VERSION ""

NS_ :

BS_:

BU_: VCU BMS DD STMM MM5 PDM MM52 RAND

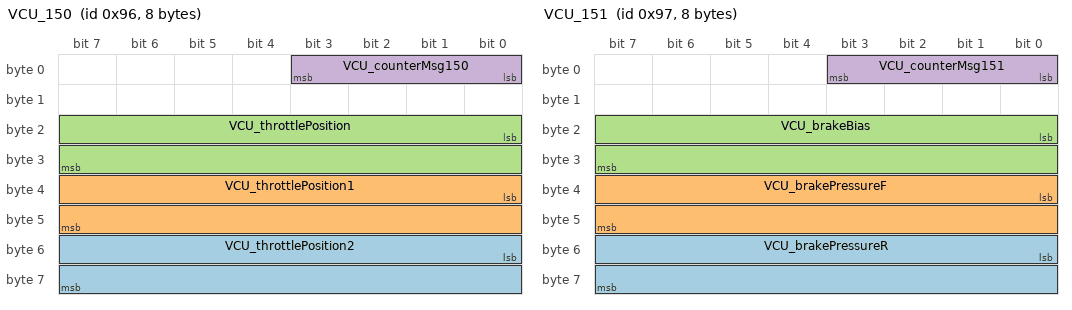
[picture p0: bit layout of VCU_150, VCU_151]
BO_ 150 VCU_150: 8 VCU
 SG_ VCU_throttlePosition2 : 48|16@1- (0.1,0) [0|100] "%" Vector__XXX
 SG_ VCU_throttlePosition1 : 32|16@1- (0.1,0) [0|100] "%" Vector__XXX
 SG_ VCU_throttlePosition : 16|16@1- (0.1,0) [0|100] "%" Vector__XXX
 SG_ VCU_counterMsg150 : 0|4@1+ (1,0) [0|15] "" Vector__XXX

BO_ 151 VCU_151: 8 VCU
 SG_ VCU_brakePressureR : 48|16@1- (0.1,0) [0|2000] "psi" Vector__XXX
 SG_ VCU_brakePressureF : 32|16@1- (0.1,0) [0|2000] "psi" Vector__XXX
 SG_ VCU_brakeBias : 16|16@1- (0.1,0) [-3276.8|3276.7] "%" Vector__XXX
 SG_ VCU_counterMsg151 : 0|4@1+ (1,0) [0|15] "" Vector__XXX

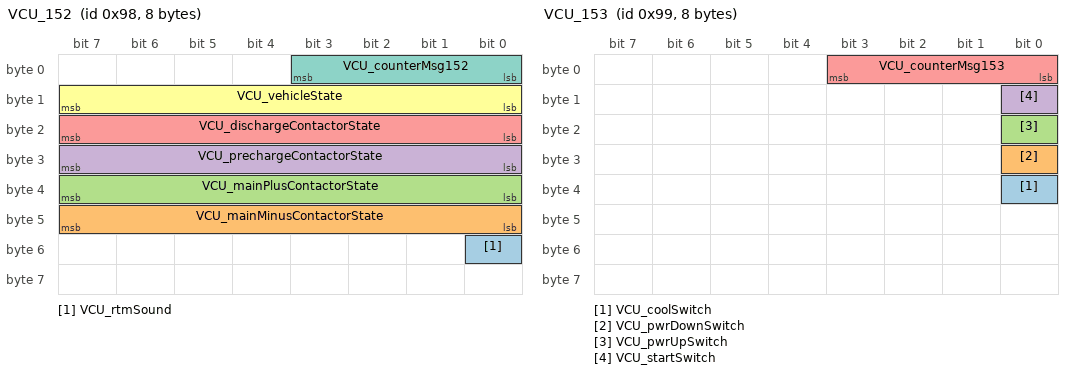
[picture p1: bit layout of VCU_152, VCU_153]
BO_ 152 VCU_152: 8 VCU
 SG_ VCU_rtmSound : 48|1@1+ (1,0) [0|1] "" Vector__XXX
 SG_ VCU_mainMinusContactorState : 40|8@1+ (1,0) [0|255] "" Vector__XXX
 SG_ VCU_mainPlusContactorState : 32|8@1+ (1,0) [0|255] "" Vector__XXX
 SG_ VCU_prechargeContactorState : 24|8@1+ (1,0) [0|255] "" Vector__XXX
 SG_ VCU_dischargeContactorState : 16|8@1+ (1,0) [0|255] "" Vector__XXX
 SG_ VCU_vehicleState : 8|8@1+ (1,0) [0|255] "" Vector__XXX
 SG_ VCU_counterMsg152 : 0|4@1+ (1,0) [0|15] "" Vector__XXX

BO_ 153 VCU_153: 8 VCU
 SG_ VCU_coolSwitch : 32|1@1+ (1,0) [0|1] "" Vector__XXX
 SG_ VCU_pwrDownSwitch : 24|1@1+ (1,0) [0|1] "" Vector__XXX
 SG_ VCU_pwrUpSwitch : 16|1@1+ (1,0) [0|1] "" Vector__XXX
 SG_ VCU_startSwitch : 8|1@1+ (1,0) [0|1] "" Vector__XXX
 SG_ VCU_counterMsg153 : 0|4@1+ (1,0) [0|15] "" Vector__XXX

BO_ 154 VCU_154: 8 VCU
 SG_ VCU_rotorTempFR : 32|16@1- (0.1,0) [-20|3276.7] "degC" Vector__XXX
 SG_ VCU_rotorTempFL : 16|16@1- (0.1,0) [-20|3276.7] "degC" Vector__XXX
 SG_ VCU_counterMsg154 : 0|4@1+ (1,0) [0|15] "" Vector__XXX

BO_ 155 VCU_155: 8 VCU
 SG_ VCU_rotorTempRR : 32|16@1- (0.1,0) [-20|3276.7] "degC" Vector__XXX
 SG_ VCU_rotorTempRL : 16|16@1- (0.1,0) [-20|3276.7] "degC" Vector__XXX
 SG_ VCU_counterMsg155 : 0|4@1+ (1,0) [0|15] "" Vector__XXX

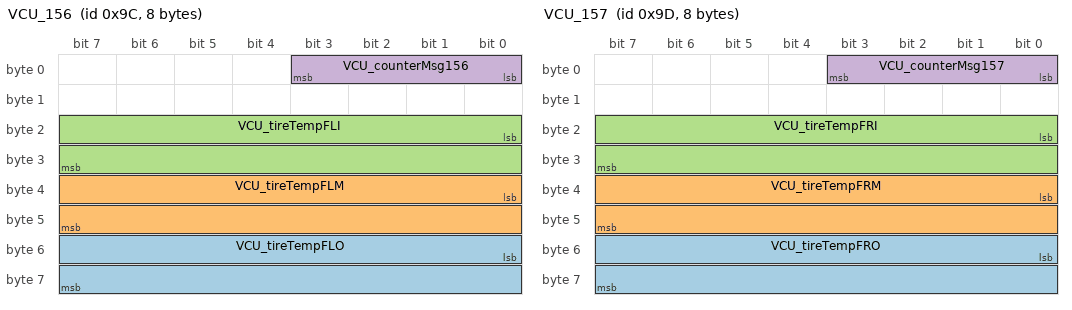
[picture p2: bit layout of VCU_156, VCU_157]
BO_ 156 VCU_156: 8 VCU
 SG_ VCU_tireTempFLO : 48|16@1- (0.1,0) [-20|3276.7] "degC" Vector__XXX
 SG_ VCU_tireTempFLM : 32|16@1- (0.1,0) [-20|3276.7] "degC" Vector__XXX
 SG_ VCU_tireTempFLI : 16|16@1- (0.1,0) [-20|3276.7] "degC" Vector__XXX
 SG_ VCU_counterMsg156 : 0|4@1+ (1,0) [0|15] "" Vector__XXX

BO_ 157 VCU_157: 8 VCU
 SG_ VCU_tireTempFRO : 48|16@1- (0.1,0) [-20|3276.7] "degC" Vector__XXX
 SG_ VCU_tireTempFRM : 32|16@1- (0.1,0) [-20|3276.7] "degC" Vector__XXX
 SG_ VCU_tireTempFRI : 16|16@1- (0.1,0) [-20|3276.7] "degC" Vector__XXX
 SG_ VCU_counterMsg157 : 0|4@1+ (1,0) [0|15] "" Vector__XXX

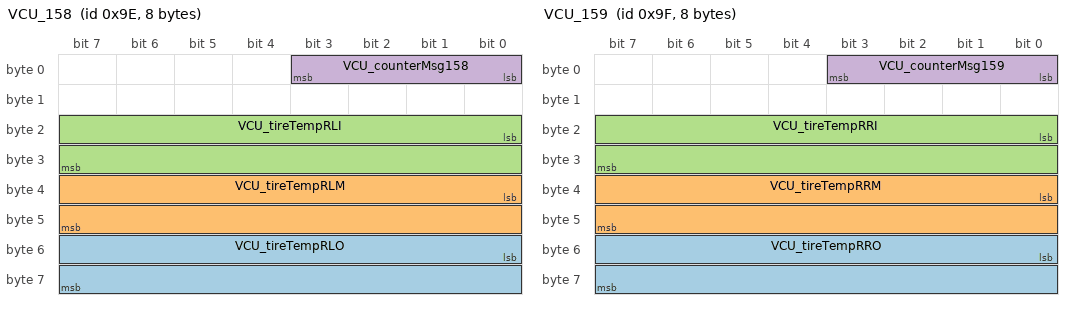
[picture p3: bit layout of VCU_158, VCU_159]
BO_ 158 VCU_158: 8 VCU
 SG_ VCU_tireTempRLO : 48|16@1- (0.1,0) [-20|3276.7] "degC" Vector__XXX
 SG_ VCU_tireTempRLM : 32|16@1- (0.1,0) [-20|3276.7] "degC" Vector__XXX
 SG_ VCU_tireTempRLI : 16|16@1- (0.1,0) [-20|3276.7] "degC" Vector__XXX
 SG_ VCU_counterMsg158 : 0|4@1+ (1,0) [0|15] "" Vector__XXX

BO_ 159 VCU_159: 8 VCU
 SG_ VCU_tireTempRRO : 48|16@1- (0.1,0) [-20|3276.7] "degC" Vector__XXX
 SG_ VCU_tireTempRRM : 32|16@1- (0.1,0) [-20|3276.7] "degC" Vector__XXX
 SG_ VCU_tireTempRRI : 16|16@1- (0.1,0) [-20|3276.7] "degC" Vector__XXX
 SG_ VCU_counterMsg159 : 0|4@1+ (1,0) [0|15] "" Vector__XXX

BO_ 160 VCU_160: 8 VCU
 SG_ VCU_driveSpeed : 16|16@1- (0.1,0) [-20|3276.7] "mph" Vector__XXX
 SG_ VCU_counterMsg160 : 0|4@1+ (1,0) [0|15] "" Vector__XXX

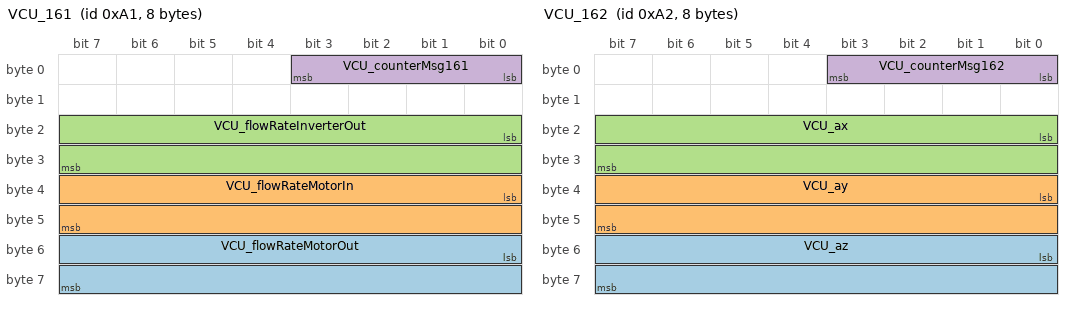
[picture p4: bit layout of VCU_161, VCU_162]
BO_ 161 VCU_161: 8 VCU
 SG_ VCU_flowRateMotorOut : 48|16@1- (0.1,0) [-10|30] "lpm" Vector__XXX
 SG_ VCU_flowRateMotorIn : 32|16@1- (0.1,0) [-10|30] "lpm" Vector__XXX
 SG_ VCU_flowRateInverterOut : 16|16@1- (0.1,0) [-10|30] "lpm" Vector__XXX
 SG_ VCU_counterMsg161 : 0|4@1+ (1,0) [0|15] "" Vector__XXX

BO_ 162 VCU_162: 8 VCU
 SG_ VCU_az : 48|16@1- (0.001,0) [-5|5] "g" Vector__XXX
 SG_ VCU_ay : 32|16@1- (0.001,0) [-5|5] "g" Vector__XXX
 SG_ VCU_ax : 16|16@1- (0.001,0) [-5|5] "g" Vector__XXX
 SG_ VCU_counterMsg162 : 0|4@1+ (1,0) [0|15] "" Vector__XXX

BO_ 163 VCU_163: 8 VCU
 SG_ VCU_susTravelRL : 48|16@1+ (0.001,0) [-100|100] "" Vector__XXX
 SG_ VCU_susTravelRR : 32|16@1+ (0.001,0) [-100|100] "" Vector__XXX
 SG_ VCU_susTravelFL : 16|16@1+ (0.001,0) [-100|100] "" Vector__XXX
 SG_ VCU_susTravelFR : 0|16@1+ (0.001,0) [-100|100] "" Vector__XXX

BO_ 164 VCU_164: 8 VCU
 SG_ VCU_torqueProfile : 16|16@1+ (1,0) [0|10] "en" Vector__XXX
 SG_ VCU_assistedTorque : 0|16@1- (0.1,0) [-230|230] "Nm" Vector__XXX

BO_ 200 BMS_200: 8 BMS
 SG_ BMS_packSOC : 48|8@1- (0.5,0) [0|100] "%" Vector__XXX
 SG_ BMS_packVolt : 32|16@1- (0.1,0) [-3276.8|3276.7] "V" Vector__XXX
 SG_ BMS_packCurr : 16|16@1- (0.1,0) [-3276.8|3276.7] "A" Vector__XXX
 SG_ BMS_rollingCounter200 : 0|8@1+ (1,0) [0|255] "" Vector__XXX

BO_ 201 BMS_201: 8 BMS
 SG_ BMS_minPackVolt : 48|16@1- (0.1,0) [-3276.8|3276.7] "V" Vector__XXX
 SG_ BMS_maxPackVolt : 32|16@1- (0.1,0) [-3276.8|3276.7] "V" Vector__XXX
 SG_ BMS_packSummedVolt : 16|16@1- (0.01,0) [-327.68|327.67] "V" Vector__XXX
 SG_ BMS_rollingCounter201 : 0|8@1+ (1,0) [0|255] "" Vector__XXX

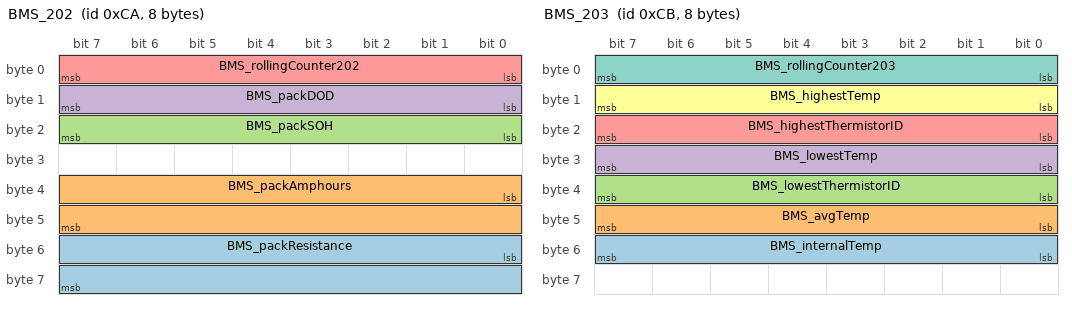
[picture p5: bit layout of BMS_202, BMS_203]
BO_ 202 BMS_202: 8 BMS
 SG_ BMS_packResistance : 48|16@1- (1,0) [-32768|32767] "mOhm" Vector__XXX
 SG_ BMS_packAmphours : 32|16@1- (0.1,0) [-3276.8|3276.7] "Ahr" Vector__XXX
 SG_ BMS_packSOH : 16|8@1- (1,0) [0|100] "%" Vector__XXX
 SG_ BMS_packDOD : 8|8@1- (0.5,0) [0|100] "%" Vector__XXX
 SG_ BMS_rollingCounter202 : 0|8@1+ (1,0) [0|255] "" Vector__XXX

BO_ 203 BMS_203: 8 BMS
 SG_ BMS_internalTemp : 48|8@1- (1,0) [-5|100] "degC" Vector__XXX
 SG_ BMS_avgTemp : 40|8@1- (1,0) [-5|100] "degC" Vector__XXX
 SG_ BMS_lowestThermistorID : 32|8@1+ (1,0) [1|180] "" Vector__XXX
 SG_ BMS_lowestTemp : 24|8@1- (1,0) [-5|100] "degC" Vector__XXX
 SG_ BMS_highestThermistorID : 16|8@1+ (1,0) [1|180] "" Vector__XXX
 SG_ BMS_highestTemp : 8|8@1- (1,0) [-5|100] "degC" Vector__XXX
 SG_ BMS_rollingCounter203 : 0|8@1+ (1,0) [0|255] "" Vector__XXX

BO_ 204 BMS_204: 8 BMS
 SG_ BMS_avgCellVolt : 48|16@1- (0.0001,0) [-3.2768|3.2767] "V" Vector__XXX
 SG_ BMS_highCellVolt : 32|16@1- (0.0001,0) [-3.2768|3.2767] "V" Vector__XXX
 SG_ BMS_lowCellVolt : 16|16@1- (0.0001,0) [-3.2768|3.2767] "V" Vector__XXX
 SG_ BMS_rollingCounter204 : 0|8@1+ (1,0) [0|255] "" Vector__XXX

BO_ 205 BMS_205: 8 BMS
 SG_ BMS_avgCellOpenVolt : 48|16@1- (0.0001,0) [-3.2768|3.2767] "V" Vector__XXX
 SG_ BMS_highCellOpenVolt : 32|16@1- (0.0001,0) [-3.2768|3.2767] "V" Vector__XXX
 SG_ BMS_lowCellOpenVolt : 16|16@1- (0.0001,0) [-3.2768|3.2767] "V" Vector__XXX
 SG_ BMS_rollingCounter205 : 0|8@1+ (1,0) [0|255] "" Vector__XXX

BO_ 206 BMS_206: 8 BMS
 SG_ BMS_avgCellInternalResistance : 48|16@1- (0.01,0) [-327.68|327.67] "mOhm" Vector__XXX
 SG_ BMS_highCellInternalResistance : 32|16@1- (0.01,0) [-327.68|327.67] "mOhm" Vector__XXX
 SG_ BMS_lowCellInternalResistance : 16|16@1- (0.01,0) [-327.68|327.67] "mOhm" Vector__XXX
 SG_ BMS_rollingCounter206 : 0|8@1+ (1,0) [0|255] "" Vector__XXX

BO_ 207 BMS_207: 8 BMS
 SG_ BMS_pwrInputVolt : 48|16@1- (0.1,0) [-3276.8|3276.7] "V" Vector__XXX
 SG_ BMS_minCellVolt : 32|16@1- (0.0001,0) [-3.2768|3.2767] "V" Vector__XXX
 SG_ BMS_maxCellVolt : 16|16@1- (0.0001,0) [-3.2768|3.2767] "V" Vector__XXX
 SG_ BMS_rollingCounter207 : 0|8@1+ (1,0) [0|255] "" Vector__XXX

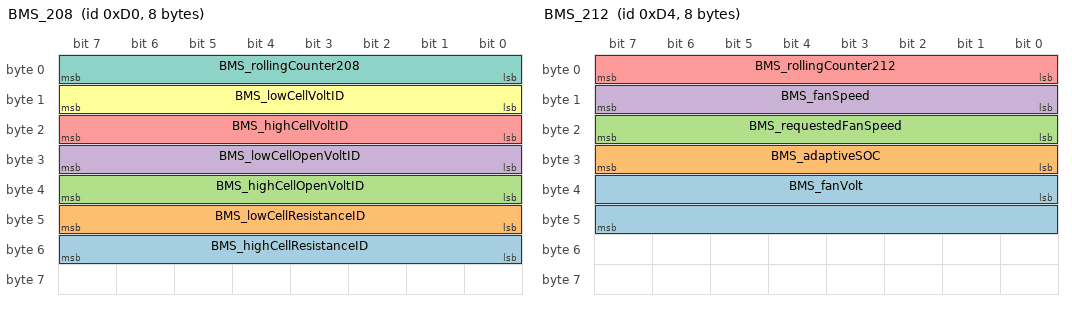
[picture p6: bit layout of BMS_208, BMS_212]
BO_ 208 BMS_208: 8 BMS
 SG_ BMS_highCellResistanceID : 48|8@1+ (1,0) [1|180] "" Vector__XXX
 SG_ BMS_lowCellResistanceID : 40|8@1+ (1,0) [1|180] "" Vector__XXX
 SG_ BMS_highCellOpenVoltID : 32|8@1+ (1,0) [1|180] "" Vector__XXX
 SG_ BMS_lowCellOpenVoltID : 24|8@1+ (1,0) [1|180] "" Vector__XXX
 SG_ BMS_highCellVoltID : 16|8@1+ (1,0) [1|180] "" Vector__XXX
 SG_ BMS_lowCellVoltID : 8|8@1+ (1,0) [1|180] "" Vector__XXX
 SG_ BMS_rollingCounter208 : 0|8@1+ (1,0) [0|255] "" Vector__XXX

BO_ 209 BMS_209: 8 BMS
 SG_ BMS_totalPackADC : 48|16@1- (0.1,0) [-3276.8|3276.7] "V" Vector__XXX
 SG_ BMS_packChargeCurrLimkW : 32|16@1- (0.1,0) [-3276.8|3276.7] "kW" Vector__XXX
 SG_ BMS_packChargeCurrLim : 16|16@1- (1,0) [-32768|32767] "A" Vector__XXX
 SG_ BMS_rollingCounter209 : 0|8@1+ (1,0) [0|255] "" Vector__XXX

BO_ 210 BMS_210: 8 BMS
 SG_ BMS_packOpenVolt : 48|16@1- (0.1,0) [-3276.8|3276.7] "V" Vector__XXX
 SG_ BMS_packDischargeCurrLimkW : 32|16@1- (0.1,0) [-3276.8|3276.7] "kW" Vector__XXX
 SG_ BMS_packDischargeCurrLim : 16|16@1- (1,0) [-32768|32767] "A" Vector__XXX
 SG_ BMS_rollingCounter210 : 0|8@1+ (1,0) [0|255] "" Vector__XXX

BO_ 211 BMS_211: 8 BMS
 SG_ BMS_avgPackCurr : 48|16@1- (0.1,0) [-3276.8|3276.7] "A" Vector__XXX
 SG_ BMS_maxPackCCL : 32|16@1- (1,0) [-32768|32767] "A" Vector__XXX
 SG_ BMS_maxPackDCL : 16|16@1- (1,0) [-32768|32767] "A" Vector__XXX
 SG_ BMS_rollingCounter211 : 0|8@1+ (1,0) [0|255] "" Vector__XXX

BO_ 212 BMS_212: 8 BMS
 SG_ BMS_fanVolt : 32|16@1- (0.01,0) [-327.68|327.67] "V" Vector__XXX
 SG_ BMS_adaptiveSOC : 24|8@1- (0.5,0) [0|100] "%" Vector__XXX
 SG_ BMS_requestedFanSpeed : 16|8@1+ (1,0) [0|6] "" Vector__XXX
 SG_ BMS_fanSpeed : 8|8@1+ (1,0) [0|6] "" Vector__XXX
 SG_ BMS_rollingCounter212 : 0|8@1+ (1,0) [0|255] "" Vector__XXX

BO_ 213 BMS_213: 8 BMS
 SG_ BMS_currLimStatus : 48|16@1+ (1,0) [0|65535] "" Vector__XXX
 SG_ BMS_adaptiveAmphours : 32|16@1- (0.1,0) [-3276.8|3276.7] "Ahr" Vector__XXX
 SG_ BMS_adaptiveTotalCapacity : 16|16@1- (0.1,0) [-3276.8|3276.7] "Ahr" Vector__XXX
 SG_ BMS_rollingCounter213 : 0|8@1+ (1,0) [0|255] "" Vector__XXX

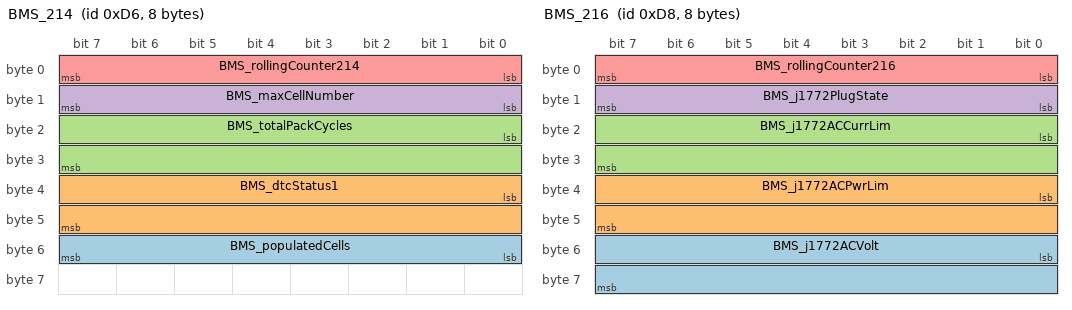
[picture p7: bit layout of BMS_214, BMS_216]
BO_ 214 BMS_214: 8 BMS
 SG_ BMS_populatedCells : 48|8@1+ (1,0) [0|255] "" Vector__XXX
 SG_ BMS_dtcStatus1 : 32|16@1+ (1,0) [0|65535] "" Vector__XXX
 SG_ BMS_totalPackCycles : 16|16@1+ (1,0) [0|65535] "Cycle" Vector__XXX
 SG_ BMS_maxCellNumber : 8|8@1+ (1,0) [0|255] "" Vector__XXX
 SG_ BMS_rollingCounter214 : 0|8@1+ (1,0) [0|255] "" Vector__XXX

BO_ 215 BMS_215: 8 BMS
 SG_ BMS_dtcStatus2 : 48|16@1+ (1,0) [0|65535] "" Vector__XXX
 SG_ BMS_failsafeStatus : 32|16@1+ (1,0) [0|65535] "" Vector__XXX
 SG_ BMS_relayState : 16|16@1+ (1,0) [0|65535] "" Vector__XXX
 SG_ BMS_rollingCounter215 : 0|8@1+ (1,0) [0|255] "" Vector__XXX

BO_ 216 BMS_216: 8 BMS
 SG_ BMS_j1772ACVolt : 48|16@1- (0.1,0) [-3276.8|3276.7] "V AC" Vector__XXX
 SG_ BMS_j1772ACPwrLim : 32|16@1- (1,0) [-32768|32767] "Watt AC" Vector__XXX
 SG_ BMS_j1772ACCurrLim : 16|16@1- (1,0) [-32768|32767] "Amp AC" Vector__XXX
 SG_ BMS_j1772PlugState : 8|8@1+ (1,0) [0|4] "" Vector__XXX
 SG_ BMS_rollingCounter216 : 0|8@1+ (1,0) [0|255] "" Vector__XXX

BO_ 217 BMS_217: 8 BMS
 SG_ BMS_contactorState : 0|3@1+ (1,0) [0|7] "enumeration" Vector__XXX

BO_ 250 DD_250: 8 DD
 SG_ DD_teensyTemp : 32|16@1- (0.1,0) [0|150] "degC" Vector__XXX
 SG_ DD_boardTemp : 16|16@1- (0.1,0) [0|150] "degC" Vector__XXX
 SG_ DD_counterMsg250 : 0|4@1+ (1,0) [0|15] "" Vector__XXX

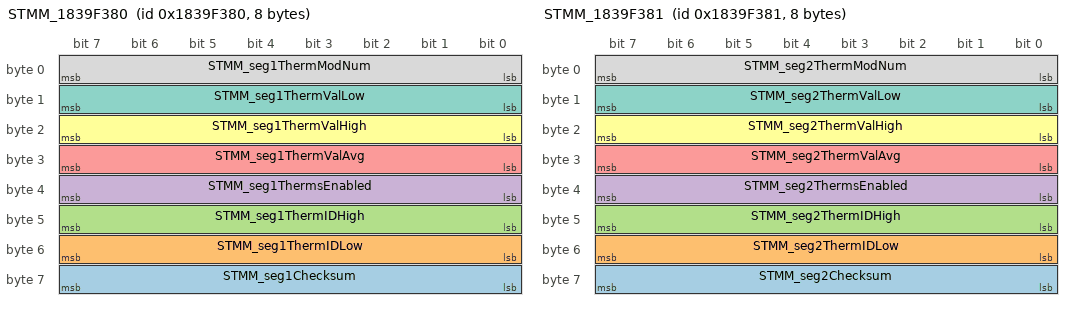
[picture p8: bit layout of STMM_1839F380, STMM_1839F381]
BO_ 406451072 STMM_1839F380: 8 STMM
 SG_ STMM_seg1Checksum : 56|8@1+ (1,0) [0|255] "" Vector__XXX
 SG_ STMM_seg1ThermIDLow : 48|8@1+ (1,0) [0|255] "" Vector__XXX
 SG_ STMM_seg1ThermIDHigh : 40|8@1+ (1,0) [0|255] "" Vector__XXX
 SG_ STMM_seg1ThermsEnabled : 32|8@1+ (1,0) [0|255] "" Vector__XXX
 SG_ STMM_seg1ThermValAvg : 24|8@1- (1,0) [-128|127] "amb" Vector__XXX
 SG_ STMM_seg1ThermValHigh : 16|8@1- (1,0) [-128|127] "amb" Vector__XXX
 SG_ STMM_seg1ThermValLow : 8|8@1- (1,0) [-128|127] "amb" Vector__XXX
 SG_ STMM_seg1ThermModNum : 0|8@1+ (1,0) [0|255] "" Vector__XXX

BO_ 406451073 STMM_1839F381: 8 STMM
 SG_ STMM_seg2Checksum : 56|8@1+ (1,0) [0|255] "" Vector__XXX
 SG_ STMM_seg2ThermIDLow : 48|8@1+ (1,0) [0|255] "" Vector__XXX
 SG_ STMM_seg2ThermIDHigh : 40|8@1+ (1,0) [0|255] "" Vector__XXX
 SG_ STMM_seg2ThermsEnabled : 32|8@1+ (1,0) [0|255] "" Vector__XXX
 SG_ STMM_seg2ThermValAvg : 24|8@1- (1,0) [-128|127] "amb" Vector__XXX
 SG_ STMM_seg2ThermValHigh : 16|8@1- (1,0) [-128|127] "amb" Vector__XXX
 SG_ STMM_seg2ThermValLow : 8|8@1- (1,0) [-128|127] "amb" Vector__XXX
 SG_ STMM_seg2ThermModNum : 0|8@1+ (1,0) [0|255] "" Vector__XXX

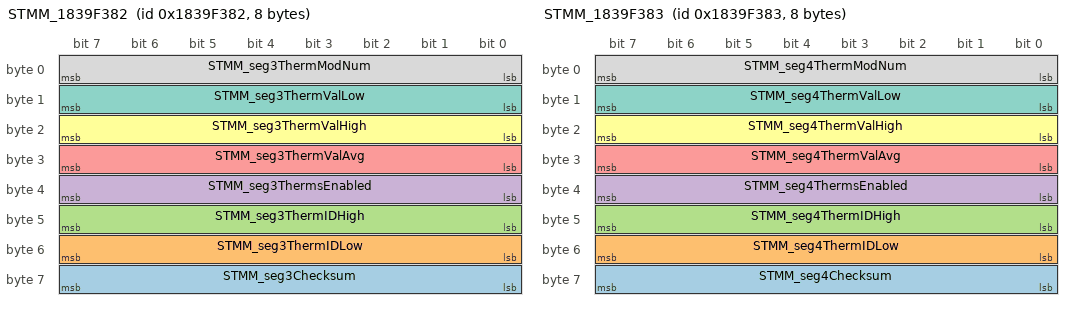
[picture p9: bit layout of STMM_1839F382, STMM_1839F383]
BO_ 406451074 STMM_1839F382: 8 STMM
 SG_ STMM_seg3Checksum : 56|8@1+ (1,0) [0|255] "" Vector__XXX
 SG_ STMM_seg3ThermIDLow : 48|8@1+ (1,0) [0|255] "" Vector__XXX
 SG_ STMM_seg3ThermIDHigh : 40|8@1+ (1,0) [0|255] "" Vector__XXX
 SG_ STMM_seg3ThermsEnabled : 32|8@1+ (1,0) [0|255] "" Vector__XXX
 SG_ STMM_seg3ThermValAvg : 24|8@1- (1,0) [-128|127] "amb" Vector__XXX
 SG_ STMM_seg3ThermValHigh : 16|8@1- (1,0) [-128|127] "amb" Vector__XXX
 SG_ STMM_seg3ThermValLow : 8|8@1- (1,0) [-128|127] "amb" Vector__XXX
 SG_ STMM_seg3ThermModNum : 0|8@1+ (1,0) [0|255] "" Vector__XXX

BO_ 406451075 STMM_1839F383: 8 STMM
 SG_ STMM_seg4Checksum : 56|8@1+ (1,0) [0|255] "" Vector__XXX
 SG_ STMM_seg4ThermIDLow : 48|8@1+ (1,0) [0|255] "" Vector__XXX
 SG_ STMM_seg4ThermIDHigh : 40|8@1+ (1,0) [0|255] "" Vector__XXX
 SG_ STMM_seg4ThermsEnabled : 32|8@1+ (1,0) [0|255] "" Vector__XXX
 SG_ STMM_seg4ThermValAvg : 24|8@1- (1,0) [-128|127] "amb" Vector__XXX
 SG_ STMM_seg4ThermValHigh : 16|8@1- (1,0) [-128|127] "amb" Vector__XXX
 SG_ STMM_seg4ThermValLow : 8|8@1- (1,0) [-128|127] "amb" Vector__XXX
 SG_ STMM_seg4ThermModNum : 0|8@1+ (1,0) [0|255] "" Vector__XXX

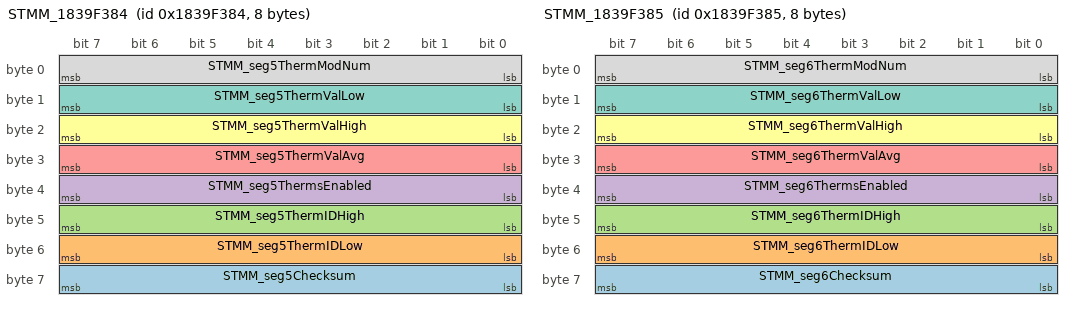
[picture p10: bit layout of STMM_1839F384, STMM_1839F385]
BO_ 406451076 STMM_1839F384: 8 STMM
 SG_ STMM_seg5Checksum : 56|8@1+ (1,0) [0|255] "" Vector__XXX
 SG_ STMM_seg5ThermIDLow : 48|8@1+ (1,0) [0|255] "" Vector__XXX
 SG_ STMM_seg5ThermIDHigh : 40|8@1+ (1,0) [0|255] "" Vector__XXX
 SG_ STMM_seg5ThermsEnabled : 32|8@1+ (1,0) [0|255] "" Vector__XXX
 SG_ STMM_seg5ThermValAvg : 24|8@1- (1,0) [-128|127] "amb" Vector__XXX
 SG_ STMM_seg5ThermValHigh : 16|8@1- (1,0) [-128|127] "amb" Vector__XXX
 SG_ STMM_seg5ThermValLow : 8|8@1- (1,0) [-128|127] "amb" Vector__XXX
 SG_ STMM_seg5ThermModNum : 0|8@1+ (1,0) [0|255] "" Vector__XXX

BO_ 406451077 STMM_1839F385: 8 STMM
 SG_ STMM_seg6Checksum : 56|8@1+ (1,0) [0|255] "" Vector__XXX
 SG_ STMM_seg6ThermIDLow : 48|8@1+ (1,0) [0|255] "" Vector__XXX
 SG_ STMM_seg6ThermIDHigh : 40|8@1+ (1,0) [0|255] "" Vector__XXX
 SG_ STMM_seg6ThermsEnabled : 32|8@1+ (1,0) [0|255] "" Vector__XXX
 SG_ STMM_seg6ThermValAvg : 24|8@1- (1,0) [-128|127] "" Vector__XXX
 SG_ STMM_seg6ThermValHigh : 16|8@1- (1,0) [-128|127] "" Vector__XXX
 SG_ STMM_seg6ThermValLow : 8|8@1- (1,0) [-128|127] "" Vector__XXX
 SG_ STMM_seg6ThermModNum : 0|8@1+ (1,0) [0|255] "" Vector__XXX

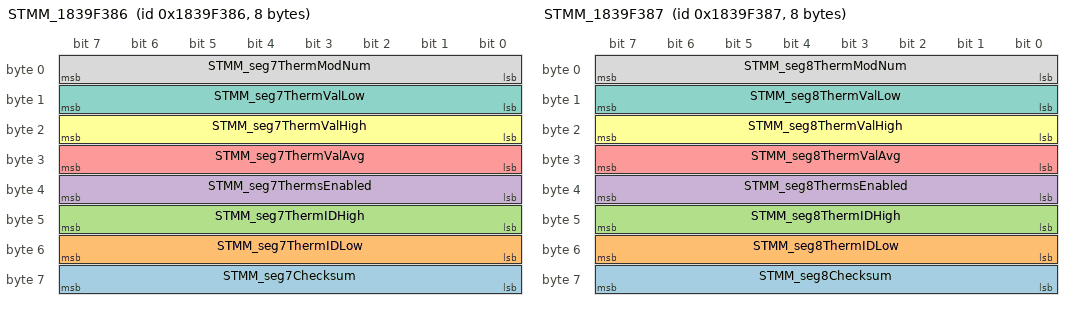
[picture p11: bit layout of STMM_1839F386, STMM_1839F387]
BO_ 406451078 STMM_1839F386: 8 STMM
 SG_ STMM_seg7Checksum : 56|8@1+ (1,0) [0|255] "" Vector__XXX
 SG_ STMM_seg7ThermIDLow : 48|8@1+ (1,0) [0|255] "" Vector__XXX
 SG_ STMM_seg7ThermIDHigh : 40|8@1+ (1,0) [0|255] "" Vector__XXX
 SG_ STMM_seg7ThermsEnabled : 32|8@1+ (1,0) [0|255] "" Vector__XXX
 SG_ STMM_seg7ThermValAvg : 24|8@1- (1,0) [-128|127] "" Vector__XXX
 SG_ STMM_seg7ThermValHigh : 16|8@1- (1,0) [-128|127] "" Vector__XXX
 SG_ STMM_seg7ThermValLow : 8|8@1- (1,0) [-128|127] "" Vector__XXX
 SG_ STMM_seg7ThermModNum : 0|8@1+ (1,0) [0|255] "" Vector__XXX

BO_ 406451079 STMM_1839F387: 8 STMM
 SG_ STMM_seg8Checksum : 56|8@1+ (1,0) [0|255] "" Vector__XXX
 SG_ STMM_seg8ThermIDLow : 48|8@1+ (1,0) [0|255] "" Vector__XXX
 SG_ STMM_seg8ThermIDHigh : 40|8@1+ (1,0) [0|255] "" Vector__XXX
 SG_ STMM_seg8ThermsEnabled : 32|8@1+ (1,0) [0|255] "" Vector__XXX
 SG_ STMM_seg8ThermValAvg : 24|8@1- (1,0) [-128|127] "" Vector__XXX
 SG_ STMM_seg8ThermValHigh : 16|8@1- (1,0) [-128|127] "" Vector__XXX
 SG_ STMM_seg8ThermValLow : 8|8@1- (1,0) [-128|127] "" Vector__XXX
 SG_ STMM_seg8ThermModNum : 0|8@1+ (1,0) [0|255] "" Vector__XXX

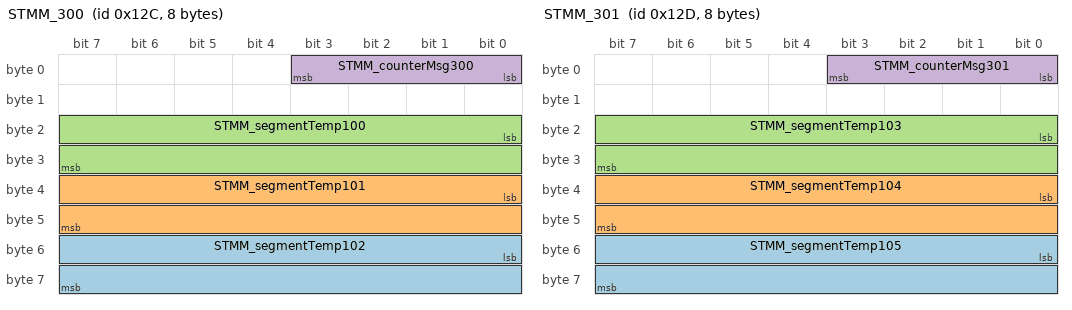
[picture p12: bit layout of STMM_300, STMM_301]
BO_ 300 STMM_300: 8 STMM
 SG_ STMM_segmentTemp102 : 48|16@1- (0.1,0) [-5|120] "" Vector__XXX
 SG_ STMM_segmentTemp101 : 32|16@1- (0.1,0) [-5|120] "" Vector__XXX
 SG_ STMM_segmentTemp100 : 16|16@1- (0.1,0) [-5|120] "" Vector__XXX
 SG_ STMM_counterMsg300 : 0|4@1+ (1,0) [0|15] "" Vector__XXX

BO_ 301 STMM_301: 8 STMM
 SG_ STMM_segmentTemp105 : 48|16@1- (0.1,0) [-5|120] "" Vector__XXX
 SG_ STMM_segmentTemp104 : 32|16@1- (0.1,0) [-5|120] "" Vector__XXX
 SG_ STMM_segmentTemp103 : 16|16@1- (0.1,0) [-5|120] "" Vector__XXX
 SG_ STMM_counterMsg301 : 0|4@1+ (1,0) [0|15] "" Vector__XXX

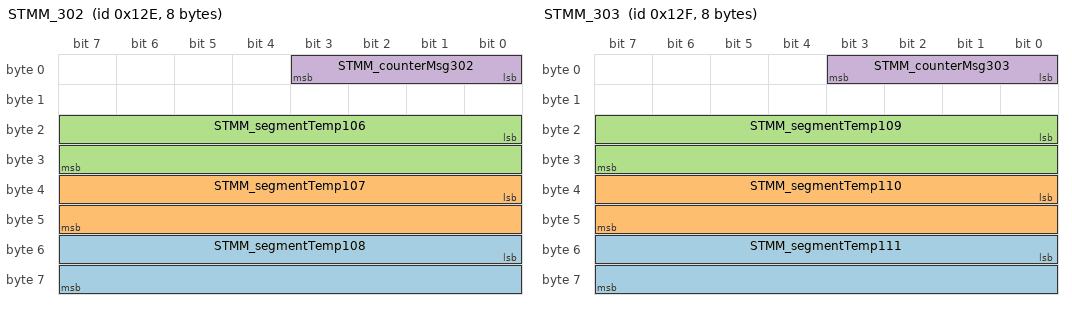
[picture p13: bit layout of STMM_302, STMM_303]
BO_ 302 STMM_302: 8 STMM
 SG_ STMM_segmentTemp108 : 48|16@1- (0.1,0) [-5|120] "" Vector__XXX
 SG_ STMM_segmentTemp107 : 32|16@1- (0.1,0) [-5|120] "" Vector__XXX
 SG_ STMM_segmentTemp106 : 16|16@1- (0.1,0) [-5|120] "" Vector__XXX
 SG_ STMM_counterMsg302 : 0|4@1+ (1,0) [0|15] "" Vector__XXX

BO_ 303 STMM_303: 8 STMM
 SG_ STMM_segmentTemp111 : 48|16@1- (0.1,0) [-5|120] "" Vector__XXX
 SG_ STMM_segmentTemp110 : 32|16@1- (0.1,0) [-5|120] "" Vector__XXX
 SG_ STMM_segmentTemp109 : 16|16@1- (0.1,0) [-5|120] "" Vector__XXX
 SG_ STMM_counterMsg303 : 0|4@1+ (1,0) [0|15] "" Vector__XXX

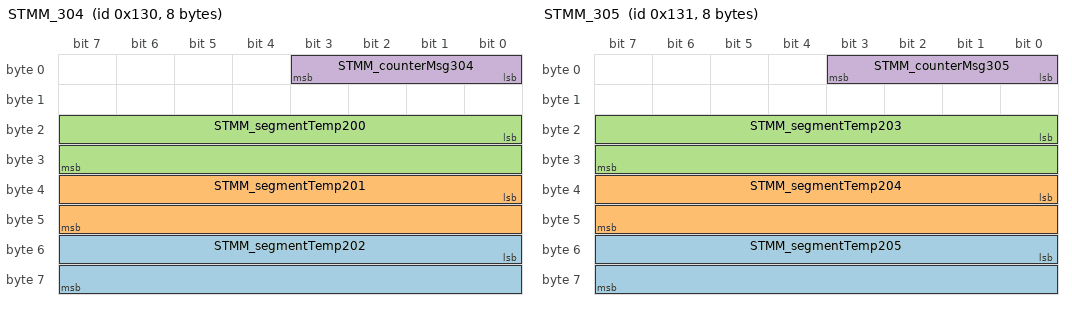
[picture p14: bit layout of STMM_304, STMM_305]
BO_ 304 STMM_304: 8 STMM
 SG_ STMM_segmentTemp202 : 48|16@1- (0.1,0) [-5|120] "" Vector__XXX
 SG_ STMM_segmentTemp201 : 32|16@1- (0.1,0) [-5|120] "" Vector__XXX
 SG_ STMM_segmentTemp200 : 16|16@1- (0.1,0) [-5|120] "" Vector__XXX
 SG_ STMM_counterMsg304 : 0|4@1+ (1,0) [0|15] "" Vector__XXX

BO_ 305 STMM_305: 8 STMM
 SG_ STMM_segmentTemp205 : 48|16@1- (0.1,0) [-5|120] "" Vector__XXX
 SG_ STMM_segmentTemp204 : 32|16@1- (0.1,0) [-5|120] "" Vector__XXX
 SG_ STMM_segmentTemp203 : 16|16@1- (0.1,0) [-5|120] "" Vector__XXX
 SG_ STMM_counterMsg305 : 0|4@1+ (1,0) [0|15] "" Vector__XXX

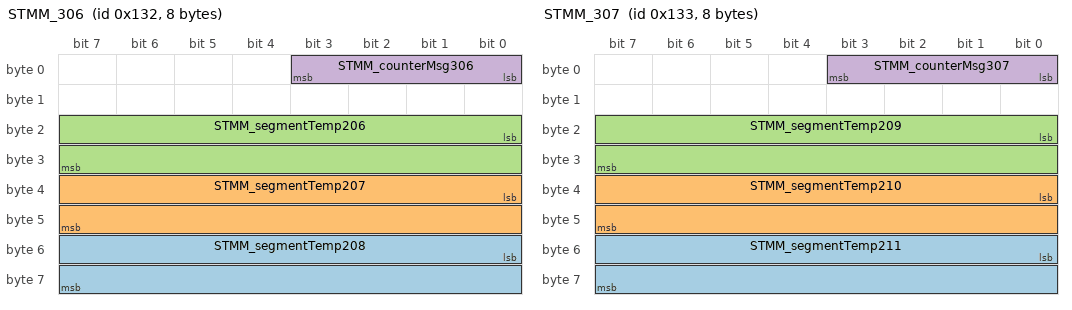
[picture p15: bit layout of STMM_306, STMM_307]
BO_ 306 STMM_306: 8 STMM
 SG_ STMM_segmentTemp208 : 48|16@1- (0.1,0) [-5|120] "" Vector__XXX
 SG_ STMM_segmentTemp207 : 32|16@1- (0.1,0) [-5|120] "" Vector__XXX
 SG_ STMM_segmentTemp206 : 16|16@1- (0.1,0) [-5|120] "" Vector__XXX
 SG_ STMM_counterMsg306 : 0|4@1+ (1,0) [0|15] "" Vector__XXX

BO_ 307 STMM_307: 8 STMM
 SG_ STMM_segmentTemp211 : 48|16@1- (0.1,0) [-5|120] "" Vector__XXX
 SG_ STMM_segmentTemp210 : 32|16@1- (0.1,0) [-5|120] "" Vector__XXX
 SG_ STMM_segmentTemp209 : 16|16@1- (0.1,0) [-5|120] "" Vector__XXX
 SG_ STMM_counterMsg307 : 0|4@1+ (1,0) [0|15] "" Vector__XXX

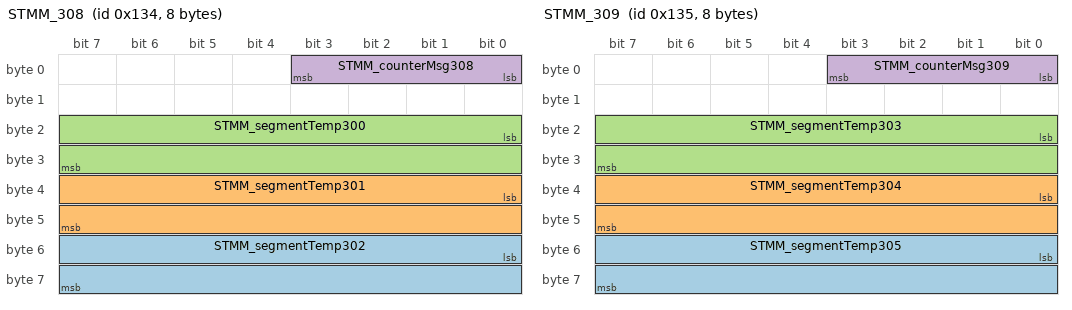
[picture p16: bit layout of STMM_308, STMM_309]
BO_ 308 STMM_308: 8 STMM
 SG_ STMM_segmentTemp302 : 48|16@1- (0.1,0) [-5|120] "" Vector__XXX
 SG_ STMM_segmentTemp301 : 32|16@1- (0.1,0) [-5|120] "" Vector__XXX
 SG_ STMM_segmentTemp300 : 16|16@1- (0.1,0) [-5|120] "" Vector__XXX
 SG_ STMM_counterMsg308 : 0|4@1+ (1,0) [0|15] "" Vector__XXX

BO_ 309 STMM_309: 8 STMM
 SG_ STMM_segmentTemp305 : 48|16@1- (0.1,0) [-5|120] "" Vector__XXX
 SG_ STMM_segmentTemp304 : 32|16@1- (0.1,0) [-5|120] "" Vector__XXX
 SG_ STMM_segmentTemp303 : 16|16@1- (0.1,0) [-5|120] "" Vector__XXX
 SG_ STMM_counterMsg309 : 0|4@1+ (1,0) [0|15] "" Vector__XXX

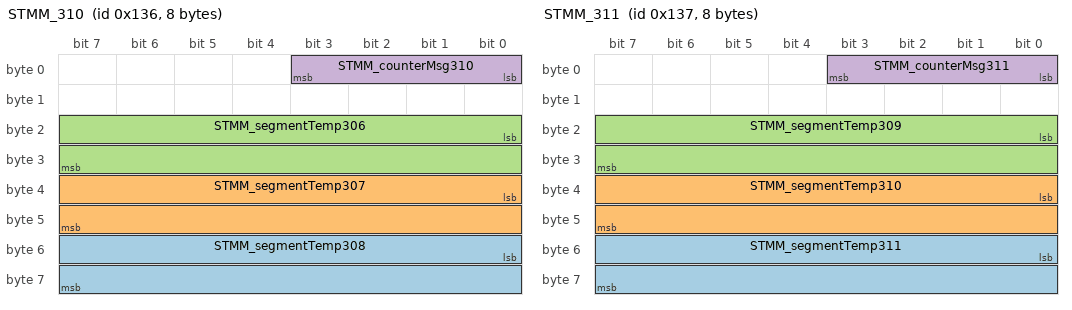
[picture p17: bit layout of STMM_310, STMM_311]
BO_ 310 STMM_310: 8 STMM
 SG_ STMM_segmentTemp308 : 48|16@1- (0.1,0) [-5|120] "" Vector__XXX
 SG_ STMM_segmentTemp307 : 32|16@1- (0.1,0) [-5|120] "" Vector__XXX
 SG_ STMM_segmentTemp306 : 16|16@1- (0.1,0) [-5|120] "" Vector__XXX
 SG_ STMM_counterMsg310 : 0|4@1+ (1,0) [0|15] "" Vector__XXX

BO_ 311 STMM_311: 8 STMM
 SG_ STMM_segmentTemp311 : 48|16@1- (0.1,0) [-5|120] "" Vector__XXX
 SG_ STMM_segmentTemp310 : 32|16@1- (0.1,0) [-5|120] "" Vector__XXX
 SG_ STMM_segmentTemp309 : 16|16@1- (0.1,0) [-5|120] "" Vector__XXX
 SG_ STMM_counterMsg311 : 0|4@1+ (1,0) [0|15] "" Vector__XXX

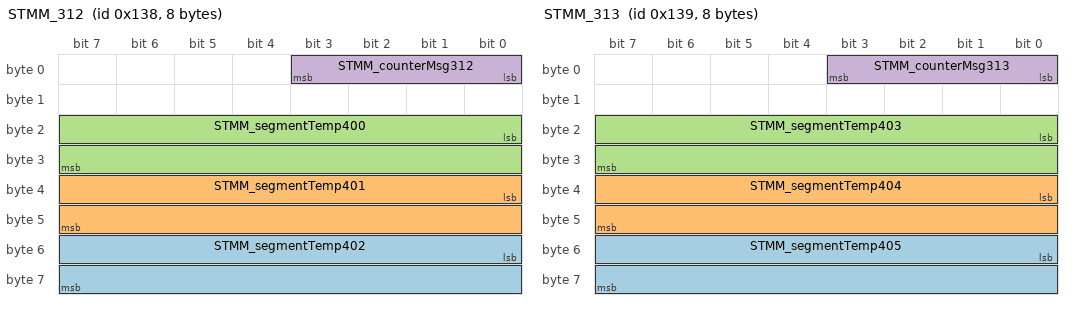
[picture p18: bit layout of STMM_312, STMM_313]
BO_ 312 STMM_312: 8 STMM
 SG_ STMM_segmentTemp402 : 48|16@1- (0.1,0) [-5|120] "" Vector__XXX
 SG_ STMM_segmentTemp401 : 32|16@1- (0.1,0) [-5|120] "" Vector__XXX
 SG_ STMM_segmentTemp400 : 16|16@1- (0.1,0) [-5|120] "" Vector__XXX
 SG_ STMM_counterMsg312 : 0|4@1+ (1,0) [0|15] "" Vector__XXX

BO_ 313 STMM_313: 8 STMM
 SG_ STMM_segmentTemp405 : 48|16@1- (0.1,0) [-5|120] "" Vector__XXX
 SG_ STMM_segmentTemp404 : 32|16@1- (0.1,0) [-5|120] "" Vector__XXX
 SG_ STMM_segmentTemp403 : 16|16@1- (0.1,0) [-5|120] "" Vector__XXX
 SG_ STMM_counterMsg313 : 0|4@1+ (1,0) [0|15] "" Vector__XXX

BO_ 314 STMM_314: 8 STMM
 SG_ STMM_segmentTemp408 : 48|16@1- (0.1,0) [-5|120] "" Vector__XXX
 SG_ STMM_segmentTemp407 : 32|16@1- (0.1,0) [-5|120] "" Vector__XXX
 SG_ STMM_segmentTemp406 : 16|16@1- (0.1,0) [-5|120] "" Vector__XXX
 SG_ STMM_counterMsg314 : 0|4@1+ (1,0) [0|15] "" Vector__XXX

BO_ 315 STMM_315: 8 STMM
 SG_ STMM_segmentTemp411 : 48|16@1- (0.1,0) [-5|120] "" Vector__XXX
 SG_ STMM_segmentTemp410 : 32|16@1- (0.1,0) [-5|120] "" Vector__XXX
 SG_ STMM_segmentTemp409 : 16|16@1- (0.1,0) [-5|120] "" Vector__XXX
 SG_ STMM_counterMsg315 : 0|4@1+ (1,0) [0|15] "" Vector__XXX

BO_ 316 STMM_316: 8 STMM
 SG_ STMM_segmentTemp502 : 48|16@1- (0.1,0) [-5|120] "" Vector__XXX
 SG_ STMM_segmentTemp501 : 32|16@1- (0.1,0) [-5|120] "" Vector__XXX
 SG_ STMM_segmentTemp500 : 16|16@1- (0.1,0) [-5|120] "" Vector__XXX
 SG_ STMM_counterMsg316 : 0|4@1+ (1,0) [0|15] "" Vector__XXX

BO_ 317 STMM_317: 8 STMM
 SG_ STMM_segmentTemp505 : 48|16@1- (0.1,0) [-5|120] "" Vector__XXX
 SG_ STMM_segmentTemp504 : 32|16@1- (0.1,0) [-5|120] "" Vector__XXX
 SG_ STMM_segmentTemp503 : 16|16@1- (0.1,0) [-5|120] "" Vector__XXX
 SG_ STMM_counterMsg317 : 0|4@1+ (1,0) [0|15] "" Vector__XXX

BO_ 318 STMM_318: 8 STMM
 SG_ STMM_segmentTemp508 : 48|16@1- (0.1,0) [-5|120] "" Vector__XXX
 SG_ STMM_segmentTemp507 : 32|16@1- (0.1,0) [-5|120] "" Vector__XXX
 SG_ STMM_segmentTemp506 : 16|16@1- (0.1,0) [-5|120] "" Vector__XXX
 SG_ STMM_counterMsg318 : 0|4@1+ (1,0) [0|15] "" Vector__XXX

BO_ 319 STMM_319: 8 STMM
 SG_ STMM_segmentTemp511 : 48|16@1- (0.1,0) [-5|120] "" Vector__XXX
 SG_ STMM_segmentTemp510 : 32|16@1- (0.1,0) [-5|120] "" Vector__XXX
 SG_ STMM_segmentTemp509 : 16|16@1- (0.1,0) [-5|120] "" Vector__XXX
 SG_ STMM_counterMsg319 : 0|4@1+ (1,0) [0|15] "" Vector__XXX

BO_ 320 STMM_320: 8 STMM
 SG_ STMM_segmentTemp602 : 48|16@1- (0.1,0) [-5|120] "" Vector__XXX
 SG_ STMM_segmentTemp601 : 32|16@1- (0.1,0) [-5|120] "" Vector__XXX
 SG_ STMM_segmentTemp600 : 16|16@1- (0.1,0) [-5|120] "" Vector__XXX
 SG_ STMM_counterMsg320 : 0|4@1+ (1,0) [0|15] "" Vector__XXX

BO_ 321 STMM_321: 8 STMM
 SG_ STMM_segmentTemp605 : 48|16@1- (0.1,0) [-5|120] "" Vector__XXX
 SG_ STMM_segmentTemp604 : 32|16@1- (0.1,0) [-5|120] "" Vector__XXX
 SG_ STMM_segmentTemp603 : 16|16@1- (0.1,0) [-5|120] "" Vector__XXX
 SG_ STMM_counterMsg321 : 0|4@1+ (1,0) [0|15] "" Vector__XXX

BO_ 322 STMM_322: 8 STMM
 SG_ STMM_segmentTemp608 : 48|16@1- (0.1,0) [-5|120] "" Vector__XXX
 SG_ STMM_segmentTemp607 : 32|16@1- (0.1,0) [-5|120] "" Vector__XXX
 SG_ STMM_segmentTemp606 : 16|16@1- (0.1,0) [-5|120] "" Vector__XXX
 SG_ STMM_counterMsg322 : 0|4@1+ (1,0) [0|15] "" Vector__XXX

BO_ 323 STMM_323: 8 STMM
 SG_ STMM_segmentTemp611 : 48|16@1- (0.1,0) [-5|120] "" Vector__XXX
 SG_ STMM_segmentTemp610 : 32|16@1- (0.1,0) [-5|120] "" Vector__XXX
 SG_ STMM_segmentTemp609 : 16|16@1- (0.1,0) [-5|120] "" Vector__XXX
 SG_ STMM_counterMsg323 : 0|4@1+ (1,0) [0|15] "" Vector__XXX

BO_ 324 STMM_324: 8 STMM
 SG_ STMM_segmentTemp702 : 48|16@1- (0.1,0) [-5|120] "" Vector__XXX
 SG_ STMM_segmentTemp701 : 32|16@1- (0.1,0) [-5|120] "" Vector__XXX
 SG_ STMM_segmentTemp700 : 16|16@1- (0.1,0) [-5|120] "" Vector__XXX
 SG_ STMM_counterMsg324 : 0|4@1+ (1,0) [0|15] "" Vector__XXX

BO_ 325 STMM_325: 8 STMM
 SG_ STMM_segmentTemp705 : 48|16@1- (0.1,0) [-5|120] "" Vector__XXX
 SG_ STMM_segmentTemp704 : 32|16@1- (0.1,0) [-5|120] "" Vector__XXX
 SG_ STMM_segmentTemp703 : 16|16@1- (0.1,0) [-5|120] "" Vector__XXX
 SG_ STMM_counterMsg325 : 0|4@1+ (1,0) [0|15] "" Vector__XXX

BO_ 326 STMM_326: 8 STMM
 SG_ STMM_segmentTemp708 : 48|16@1- (0.1,0) [-5|120] "" Vector__XXX
 SG_ STMM_segmentTemp707 : 32|16@1- (0.1,0) [-5|120] "" Vector__XXX
 SG_ STMM_segmentTemp706 : 16|16@1- (0.1,0) [-5|120] "" Vector__XXX
 SG_ STMM_counterMsg326 : 0|4@1+ (1,0) [0|15] "" Vector__XXX

BO_ 327 STMM_327: 8 STMM
 SG_ STMM_segmentTemp711 : 48|16@1- (0.1,0) [-5|120] "" Vector__XXX
 SG_ STMM_segmentTemp710 : 32|16@1- (0.1,0) [-5|120] "" Vector__XXX
 SG_ STMM_segmentTemp709 : 16|16@1- (0.1,0) [-5|120] "" Vector__XXX
 SG_ STMM_counterMsg327 : 0|4@1+ (1,0) [0|15] "" Vector__XXX

BO_ 328 STMM_328: 8 STMM
 SG_ STMM_segmentTemp802 : 48|16@1- (0.1,0) [-5|120] "" Vector__XXX
 SG_ STMM_segmentTemp801 : 32|16@1- (0.1,0) [-5|120] "" Vector__XXX
 SG_ STMM_segmentTemp800 : 16|16@1- (0.1,0) [-5|120] "" Vector__XXX
 SG_ STMM_counterMsg328 : 0|4@1+ (1,0) [0|15] "" Vector__XXX

BO_ 329 STMM_329: 8 STMM
 SG_ STMM_segmentTemp805 : 48|16@1- (0.1,0) [-5|120] "" Vector__XXX
 SG_ STMM_segmentTemp804 : 32|16@1- (0.1,0) [-5|120] "" Vector__XXX
 SG_ STMM_segmentTemp803 : 16|16@1- (0.1,0) [-5|120] "" Vector__XXX
 SG_ STMM_counterMsg329 : 0|4@1+ (1,0) [0|15] "" Vector__XXX

BO_ 330 STMM_330: 8 STMM
 SG_ STMM_segmentTemp808 : 48|16@1- (0.1,0) [-5|120] "" Vector__XXX
 SG_ STMM_segmentTemp807 : 32|16@1- (0.1,0) [-5|120] "" Vector__XXX
 SG_ STMM_segmentTemp806 : 16|16@1- (0.1,0) [-5|120] "" Vector__XXX
 SG_ STMM_counterMsg330 : 0|4@1+ (1,0) [0|15] "" Vector__XXX

BO_ 331 STMM_331: 8 STMM
 SG_ STMM_segmentTemp811 : 48|16@1- (0.1,0) [-5|120] "" Vector__XXX
 SG_ STMM_segmentTemp810 : 32|16@1- (0.1,0) [-5|120] "" Vector__XXX
 SG_ STMM_segmentTemp809 : 16|16@1- (0.1,0) [-5|120] "" Vector__XXX
 SG_ STMM_counterMsg331 : 0|4@1+ (1,0) [0|15] "" Vector__XXX

BO_ 299 STMM_299: 8 STMM
 SG_ STMM_segmentSync : 8|8@1+ (1,0) [0|255] "" Vector__XXX
 SG_ STMM_counterMsg299 : 0|4@1+ (1,0) [0|15] "" Vector__XXX

BO_ 332 STMM_332: 8 STMM
 SG_ STMM_segmentVolt102 : 48|16@1- (0.001,0) [-32.768|32.767] "" Vector__XXX
 SG_ STMM_segmentVolt101 : 32|16@1- (0.001,0) [-32.768|32.767] "" Vector__XXX
 SG_ STMM_segmentVolt100 : 16|16@1- (0.001,0) [-32.768|32.767] "" Vector__XXX
 SG_ STMM_counterMsg332 : 0|4@1+ (1,0) [0|15] "" Vector__XXX

BO_ 333 STMM_333: 8 STMM
 SG_ STMM_segmentVolt105 : 48|16@1- (0.001,0) [-32.768|32.767] "" Vector__XXX
 SG_ STMM_segmentVolt104 : 32|16@1- (0.001,0) [-32.768|32.767] "" Vector__XXX
 SG_ STMM_segmentVolt103 : 16|16@1- (0.001,0) [-32.768|32.767] "" Vector__XXX
 SG_ STMM_counterMsg333 : 0|4@1+ (1,0) [0|15] "" Vector__XXX

BO_ 334 STMM_334: 8 STMM
 SG_ STMM_segmentVolt108 : 48|16@1- (0.001,0) [-32.768|32.767] "" Vector__XXX
 SG_ STMM_segmentVolt107 : 32|16@1- (0.001,0) [-32.768|32.767] "" Vector__XXX
 SG_ STMM_segmentVolt106 : 16|16@1- (0.001,0) [-32.768|32.767] "" Vector__XXX
 SG_ STMM_counterMsg334 : 0|4@1+ (1,0) [0|15] "" Vector__XXX

BO_ 335 STMM_335: 8 STMM
 SG_ STMM_segmentVolt111 : 48|16@1- (0.001,0) [-32.768|32.767] "" Vector__XXX
 SG_ STMM_segmentVolt110 : 32|16@1- (0.001,0) [-32.768|32.767] "" Vector__XXX
 SG_ STMM_segmentVolt109 : 16|16@1- (0.001,0) [-32.768|32.767] "" Vector__XXX
 SG_ STMM_counterMsg335 : 0|4@1+ (1,0) [0|15] "" Vector__XXX

BO_ 336 STMM_336: 8 STMM
 SG_ STMM_segmentVolt202 : 48|16@1- (0.001,0) [-32.768|32.767] "" Vector__XXX
 SG_ STMM_segmentVolt201 : 32|16@1- (0.001,0) [-32.768|32.767] "" Vector__XXX
 SG_ STMM_segmentVolt200 : 16|16@1- (0.001,0) [-32.768|32.767] "" Vector__XXX
 SG_ STMM_counterMsg336 : 0|4@1+ (1,0) [0|15] "" Vector__XXX

BO_ 337 STMM_337: 8 STMM
 SG_ STMM_segmentVolt205 : 48|16@1- (0.001,0) [-32.768|32.767] "" Vector__XXX
 SG_ STMM_segmentVolt204 : 32|16@1- (0.001,0) [-32.768|32.767] "" Vector__XXX
 SG_ STMM_segmentVolt203 : 16|16@1- (0.001,0) [-32.768|32.767] "" Vector__XXX
 SG_ STMM_counterMsg337 : 0|4@1+ (1,0) [0|15] "" Vector__XXX

BO_ 338 STMM_338: 8 STMM
 SG_ STMM_segmentVolt208 : 48|16@1- (0.001,0) [-32.768|32.767] "" Vector__XXX
 SG_ STMM_segmentVolt207 : 32|16@1- (0.001,0) [-32.768|32.767] "" Vector__XXX
 SG_ STMM_segmentVolt206 : 16|16@1- (0.001,0) [-32.768|32.767] "" Vector__XXX
 SG_ STMM_counterMsg338 : 0|4@1+ (1,0) [0|15] "" Vector__XXX

BO_ 339 STMM_339: 8 STMM
 SG_ STMM_segmentVolt211 : 48|16@1- (0.001,0) [-32.768|32.767] "" Vector__XXX
 SG_ STMM_segmentVolt210 : 32|16@1- (0.001,0) [-32.768|32.767] "" Vector__XXX
 SG_ STMM_segmentVolt209 : 16|16@1- (0.001,0) [-32.768|32.767] "" Vector__XXX
 SG_ STMM_counterMsg339 : 0|4@1+ (1,0) [0|15] "" Vector__XXX

BO_ 340 STMM_340: 8 STMM
 SG_ STMM_segmentVolt302 : 48|16@1- (0.001,0) [-32.768|32.767] "" Vector__XXX
 SG_ STMM_segmentVolt301 : 32|16@1- (0.001,0) [-32.768|32.767] "" Vector__XXX
 SG_ STMM_segmentVolt300 : 16|16@1- (0.001,0) [-32.768|32.767] "" Vector__XXX
 SG_ STMM_counterMsg340 : 0|4@1+ (1,0) [0|15] "" Vector__XXX

BO_ 341 STMM_341: 8 STMM
 SG_ STMM_segmentVolt305 : 48|16@1- (0.001,0) [-32.768|32.767] "" Vector__XXX
 SG_ STMM_segmentVolt304 : 32|16@1- (0.001,0) [-32.768|32.767] "" Vector__XXX
 SG_ STMM_segmentVolt303 : 16|16@1- (0.001,0) [-32.768|32.767] "" Vector__XXX
 SG_ STMM_counterMsg341 : 0|4@1+ (1,0) [0|15] "" Vector__XXX

BO_ 342 STMM_342: 8 STMM
 SG_ STMM_segmentVolt308 : 48|16@1- (0.001,0) [-32.768|32.767] "" Vector__XXX
 SG_ STMM_segmentVolt307 : 32|16@1- (0.001,0) [-32.768|32.767] "" Vector__XXX
 SG_ STMM_segmentVolt306 : 16|16@1- (0.001,0) [-32.768|32.767] "" Vector__XXX
 SG_ STMM_counterMsg342 : 0|4@1+ (1,0) [0|15] "" Vector__XXX

BO_ 343 STMM_343: 8 STMM
 SG_ STMM_segmentVolt311 : 48|16@1- (0.001,0) [-32.768|32.767] "" Vector__XXX
 SG_ STMM_segmentVolt310 : 32|16@1- (0.001,0) [-32.768|32.767] "" Vector__XXX
 SG_ STMM_segmentVolt309 : 16|16@1- (0.001,0) [-32.768|32.767] "" Vector__XXX
 SG_ STMM_counterMsg343 : 0|4@1+ (1,0) [0|15] "" Vector__XXX

BO_ 344 STMM_344: 8 STMM
 SG_ STMM_segmentVolt402 : 48|16@1- (0.001,0) [-32.768|32.767] "" Vector__XXX
 SG_ STMM_segmentVolt401 : 32|16@1- (0.001,0) [-32.768|32.767] "" Vector__XXX
 SG_ STMM_segmentVolt400 : 16|16@1- (0.001,0) [-32.768|32.767] "" Vector__XXX
 SG_ STMM_counterMsg344 : 0|4@1+ (1,0) [0|15] "" Vector__XXX

BO_ 345 STMM_345: 8 STMM
 SG_ STMM_segmentVolt405 : 48|16@1- (0.001,0) [-32.768|32.767] "" Vector__XXX
 SG_ STMM_segmentVolt404 : 32|16@1- (0.001,0) [-32.768|32.767] "" Vector__XXX
 SG_ STMM_segmentVolt403 : 16|16@1- (0.001,0) [-32.768|32.767] "" Vector__XXX
 SG_ STMM_counterMsg345 : 0|4@1+ (1,0) [0|15] "" Vector__XXX

BO_ 346 STMM_346: 8 STMM
 SG_ STMM_segmentVolt408 : 48|16@1- (0.001,0) [-32.768|32.767] "" Vector__XXX
 SG_ STMM_segmentVolt407 : 32|16@1- (0.001,0) [-32.768|32.767] "" Vector__XXX
 SG_ STMM_segmentVolt406 : 16|16@1- (0.001,0) [-32.768|32.767] "" Vector__XXX
 SG_ STMM_counterMsg346 : 0|4@1+ (1,0) [0|15] "" Vector__XXX

BO_ 347 STMM_347: 8 STMM
 SG_ STMM_segmentVolt411 : 48|16@1- (0.001,0) [-32.768|32.767] "" Vector__XXX
 SG_ STMM_segmentVolt410 : 32|16@1- (0.001,0) [-32.768|32.767] "" Vector__XXX
 SG_ STMM_segmentVolt409 : 16|16@1- (0.001,0) [-32.768|32.767] "" Vector__XXX
 SG_ STMM_counterMsg347 : 0|4@1+ (1,0) [0|15] "" Vector__XXX

BO_ 348 STMM_348: 8 STMM
 SG_ STMM_segmentVolt502 : 48|16@1- (0.001,0) [-32.768|32.767] "" Vector__XXX
 SG_ STMM_segmentVolt501 : 32|16@1- (0.001,0) [-32.768|32.767] "" Vector__XXX
 SG_ STMM_segmentVolt500 : 16|16@1- (0.001,0) [-32.768|32.767] "" Vector__XXX
 SG_ STMM_counterMsg348 : 0|4@1+ (1,0) [0|15] "" Vector__XXX

BO_ 349 STMM_349: 8 STMM
 SG_ STMM_segmentVolt505 : 48|16@1- (0.001,0) [-32.768|32.767] "" Vector__XXX
 SG_ STMM_segmentVolt504 : 32|16@1- (0.001,0) [-32.768|32.767] "" Vector__XXX
 SG_ STMM_segmentVolt503 : 16|16@1- (0.001,0) [-32.768|32.767] "" Vector__XXX
 SG_ STMM_counterMsg349 : 0|4@1+ (1,0) [0|15] "" Vector__XXX

BO_ 350 STMM_350: 8 STMM
 SG_ STMM_segmentVolt508 : 48|16@1- (0.001,0) [-32.768|32.767] "" Vector__XXX
 SG_ STMM_segmentVolt507 : 32|16@1- (0.001,0) [-32.768|32.767] "" Vector__XXX
 SG_ STMM_segmentVolt506 : 16|16@1- (0.001,0) [-32.768|32.767] "" Vector__XXX
 SG_ STMM_counterMsg350 : 0|4@1+ (1,0) [0|15] "" Vector__XXX

BO_ 351 STMM_351: 8 STMM
 SG_ STMM_segmentVolt511 : 48|16@1- (0.001,0) [-32.768|32.767] "" Vector__XXX
 SG_ STMM_segmentVolt510 : 32|16@1- (0.001,0) [-32.768|32.767] "" Vector__XXX
 SG_ STMM_segmentVolt509 : 16|16@1- (0.001,0) [-32.768|32.767] "" Vector__XXX
 SG_ STMM_counterMsg351 : 0|4@1+ (1,0) [0|15] "" Vector__XXX

BO_ 352 STMM_352: 8 STMM
 SG_ STMM_segmentVolt602 : 48|16@1- (0.001,0) [-32.768|32.767] "" Vector__XXX
 SG_ STMM_segmentVolt601 : 32|16@1- (0.001,0) [-32.768|32.767] "" Vector__XXX
 SG_ STMM_segmentVolt600 : 16|16@1- (0.001,0) [-32.768|32.767] "" Vector__XXX
 SG_ STMM_counterMsg352 : 0|4@1+ (1,0) [0|15] "" Vector__XXX

BO_ 353 STMM_353: 8 STMM
 SG_ STMM_segmentVolt605 : 48|16@1- (0.001,0) [-32.768|32.767] "" Vector__XXX
 SG_ STMM_segmentVolt604 : 32|16@1- (0.001,0) [-32.768|32.767] "" Vector__XXX
 SG_ STMM_segmentVolt603 : 16|16@1- (0.001,0) [-32.768|32.767] "" Vector__XXX
 SG_ STMM_counterMsg353 : 0|4@1+ (1,0) [0|15] "" Vector__XXX

BO_ 354 STMM_354: 8 STMM
 SG_ STMM_segmentVolt608 : 48|16@1- (0.001,0) [-32.768|32.767] "" Vector__XXX
 SG_ STMM_segmentVolt607 : 32|16@1- (0.001,0) [-32.768|32.767] "" Vector__XXX
 SG_ STMM_segmentVolt606 : 16|16@1- (0.001,0) [-32.768|32.767] "" Vector__XXX
 SG_ STMM_counterMsg354 : 0|4@1+ (1,0) [0|15] "" Vector__XXX

BO_ 355 STMM_355: 8 STMM
 SG_ STMM_segmentVolt611 : 48|16@1- (0.001,0) [-32.768|32.767] "" Vector__XXX
 SG_ STMM_segmentVolt610 : 32|16@1- (0.001,0) [-32.768|32.767] "" Vector__XXX
 SG_ STMM_segmentVolt609 : 16|16@1- (0.001,0) [-32.768|32.767] "" Vector__XXX
 SG_ STMM_counterMsg355 : 0|4@1+ (1,0) [0|15] "" Vector__XXX

BO_ 356 STMM_356: 8 STMM
 SG_ STMM_segmentVolt702 : 48|16@1- (0.001,0) [-32.768|32.767] "" Vector__XXX
 SG_ STMM_segmentVolt701 : 32|16@1- (0.001,0) [-32.768|32.767] "" Vector__XXX
 SG_ STMM_segmentVolt700 : 16|16@1- (0.001,0) [-32.768|32.767] "" Vector__XXX
 SG_ STMM_counterMsg356 : 0|4@1+ (1,0) [0|15] "" Vector__XXX

BO_ 357 STMM_357: 8 STMM
 SG_ STMM_segmentVolt705 : 48|16@1- (0.001,0) [-32.768|32.767] "" Vector__XXX
 SG_ STMM_segmentVolt704 : 32|16@1- (0.001,0) [-32.768|32.767] "" Vector__XXX
 SG_ STMM_segmentVolt703 : 16|16@1- (0.001,0) [-32.768|32.767] "" Vector__XXX
 SG_ STMM_counterMsg357 : 0|4@1+ (1,0) [0|15] "" Vector__XXX

BO_ 358 STMM_358: 8 STMM
 SG_ STMM_segmentVolt708 : 48|16@1- (0.001,0) [-32.768|32.767] "" Vector__XXX
 SG_ STMM_segmentVolt707 : 32|16@1- (0.001,0) [-32.768|32.767] "" Vector__XXX
 SG_ STMM_segmentVolt706 : 16|16@1- (0.001,0) [-32.768|32.767] "" Vector__XXX
 SG_ STMM_counterMsg358 : 0|4@1+ (1,0) [0|15] "" Vector__XXX

BO_ 359 STMM_359: 8 STMM
 SG_ STMM_segmentVolt711 : 48|16@1- (0.001,0) [-32.768|32.767] "" Vector__XXX
 SG_ STMM_segmentVolt710 : 32|16@1- (0.001,0) [-32.768|32.767] "" Vector__XXX
 SG_ STMM_segmentVolt709 : 16|16@1- (0.001,0) [-32.768|32.767] "" Vector__XXX
 SG_ STMM_counterMsg359 : 0|4@1+ (1,0) [0|15] "" Vector__XXX

BO_ 360 STMM_360: 8 STMM
 SG_ STMM_segmentVolt802 : 48|16@1- (0.001,0) [-32.768|32.767] "" Vector__XXX
 SG_ STMM_segmentVolt801 : 32|16@1- (0.001,0) [-32.768|32.767] "" Vector__XXX
 SG_ STMM_segmentVolt800 : 16|16@1- (0.001,0) [-32.768|32.767] "" Vector__XXX
 SG_ STMM_counterMsg360 : 0|4@1+ (1,0) [0|15] "" Vector__XXX

BO_ 361 STMM_361: 8 STMM
 SG_ STMM_segmentVolt805 : 48|16@1- (0.001,0) [-32.768|32.767] "" Vector__XXX
 SG_ STMM_segmentVolt804 : 32|16@1- (0.001,0) [-32.768|32.767] "" Vector__XXX
 SG_ STMM_segmentVolt803 : 16|16@1- (0.001,0) [-32.768|32.767] "" Vector__XXX
 SG_ STMM_counterMsg361 : 0|4@1+ (1,0) [0|15] "" Vector__XXX

BO_ 362 STMM_362: 8 STMM
 SG_ STMM_segmentVolt808 : 48|16@1- (0.001,0) [-32.768|32.767] "" Vector__XXX
 SG_ STMM_segmentVolt807 : 32|16@1- (0.001,0) [-32.768|32.767] "" Vector__XXX
 SG_ STMM_segmentVolt806 : 16|16@1- (0.001,0) [-32.768|32.767] "" Vector__XXX
 SG_ STMM_counterMsg362 : 0|4@1+ (1,0) [0|15] "" Vector__XXX

BO_ 363 STMM_363: 8 STMM
 SG_ STMM_segmentVolt811 : 48|16@1- (0.001,0) [-32.768|32.767] "" Vector__XXX
 SG_ STMM_segmentVolt810 : 32|16@1- (0.001,0) [-32.768|32.767] "" Vector__XXX
 SG_ STMM_segmentVolt809 : 16|16@1- (0.001,0) [-32.768|32.767] "" Vector__XXX
 SG_ STMM_counterMsg363 : 0|4@1+ (1,0) [0|15] "" Vector__XXX

BO_ 372 MM5_372: 8 MM5
 SG_ MM5_ay : 32|16@1+ (0.0001274,-4.1745795) [0|0] "g" Vector__XXX
 SG_ MM5_yawRate : 0|16@1+ (0.005,-163.9) [0|0] "deg/sec" Vector__XXX

BO_ 376 MM5_376: 8 MM5
 SG_ MM5_ax : 32|16@1+ (-0.0001274,4.1745795) [0|0] "g" Vector__XXX
 SG_ MM5_rollRate : 0|16@1+ (-0.005,163.9) [0|0] "deg/sec" Vector__XXX

BO_ 380 MM5_380: 8 MM5
 SG_ MM5_az : 32|16@1+ (-0.0001274,4.1745795) [0|0] "g" Vector__XXX

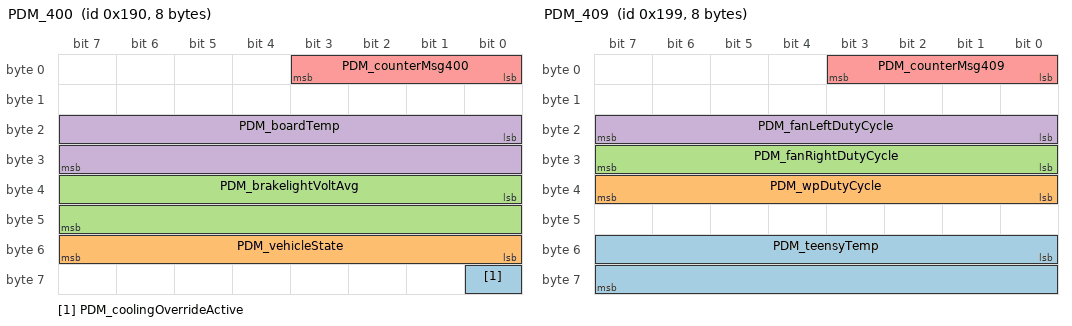
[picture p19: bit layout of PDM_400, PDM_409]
BO_ 400 PDM_400: 8 PDM
 SG_ PDM_coolingOverrideActive : 56|1@1+ (1,0) [0|0] "bool" Vector__XXX
 SG_ PDM_vehicleState : 48|8@1- (1,0) [0|3] "" Vector__XXX
 SG_ PDM_brakelightVoltAvg : 32|16@1- (0.001,0) [-5|100] "V" Vector__XXX
 SG_ PDM_boardTemp : 16|16@1- (0.1,0) [-5|100] "degC" Vector__XXX
 SG_ PDM_counterMsg400 : 0|4@1+ (1,0) [0|15] "" Vector__XXX

BO_ 401 PDM_401: 8 PDM
 SG_ PDM_pdmCurrentMin : 48|16@1- (0.01,0) [-5|20] "A" Vector__XXX
 SG_ PDM_pdmCurrentMax : 32|16@1- (0.01,0) [-5|20] "A" Vector__XXX
 SG_ PDM_pdmCurrentAvg : 16|16@1- (0.01,0) [-5|20] "A" Vector__XXX
 SG_ PDM_counterMsg401 : 0|4@1+ (1,0) [0|15] "" Vector__XXX

BO_ 402 PDM_402: 8 PDM
 SG_ PDM_pdmVoltMin : 48|16@1- (0.001,0) [-5|20] "V" Vector__XXX
 SG_ PDM_pdmVoltMax : 32|16@1- (0.001,0) [-5|20] "V" Vector__XXX
 SG_ PDM_pdmVoltAvg : 16|16@1- (0.001,0) [-5|20] "V" Vector__XXX
 SG_ PDM_counterMsg402 : 0|4@1+ (1,0) [0|15] "" Vector__XXX

BO_ 403 PDM_403: 8 PDM
 SG_ PDM_fanRightCurrentMin : 48|16@1- (0.01,0) [-5|20] "A" Vector__XXX
 SG_ PDM_fanRightCurrentMax : 32|16@1- (0.01,0) [-5|20] "A" Vector__XXX
 SG_ PDM_fanRightCurrentAvg : 16|16@1- (0.01,0) [-5|20] "A" Vector__XXX
 SG_ PDM_counterMsg403 : 0|4@1+ (1,0) [0|15] "" Vector__XXX

BO_ 404 PDM_404: 8 PDM
 SG_ PDM_fanRightVoltMin : 48|16@1- (0.001,0) [-5|20] "V" Vector__XXX
 SG_ PDM_fanRightVoltMax : 32|16@1- (0.001,0) [-5|20] "V" Vector__XXX
 SG_ PDM_fanRightVoltAvg : 16|16@1- (0.001,0) [-5|20] "V" Vector__XXX
 SG_ PDM_counterMsg404 : 0|4@1+ (1,0) [0|15] "" Vector__XXX

BO_ 405 PDM_405: 8 PDM
 SG_ PDM_fanLeftCurrentMin : 48|16@1- (0.01,0) [-5|20] "A" Vector__XXX
 SG_ PDM_fanLeftCurrentMax : 32|16@1- (0.01,0) [-5|20] "A" Vector__XXX
 SG_ PDM_fanLeftCurrentAvg : 16|16@1- (0.01,0) [-5|20] "A" Vector__XXX
 SG_ PDM_counterMsg405 : 0|4@1+ (1,0) [0|15] "" Vector__XXX

BO_ 406 PDM_406: 8 PDM
 SG_ PDM_fanLeftVoltMin : 48|16@1- (0.001,0) [-5|20] "V" Vector__XXX
 SG_ PDM_fanLeftVoltMax : 32|16@1- (0.001,0) [-5|20] "V" Vector__XXX
 SG_ PDM_fanLeftVoltAvg : 16|16@1- (0.001,0) [-5|20] "V" Vector__XXX
 SG_ PDM_counterMsg406 : 0|4@1+ (1,0) [0|15] "" Vector__XXX

BO_ 407 PDM_407: 8 PDM
 SG_ PDM_wpCurrentMin : 48|16@1- (0.01,0) [-5|20] "A" Vector__XXX
 SG_ PDM_wpCurrentMax : 32|16@1- (0.01,0) [-5|20] "A" Vector__XXX
 SG_ PDM_wpCurrentAvg : 16|16@1- (0.01,0) [-5|20] "A" Vector__XXX
 SG_ PDM_counterMsg407 : 0|4@1+ (1,0) [0|15] "" Vector__XXX

BO_ 408 PDM_408: 8 PDM
 SG_ PDM_wpVoltMin : 48|16@1- (0.001,0) [-5|20] "V" Vector__XXX
 SG_ PDM_wpVoltMax : 32|16@1- (0.001,0) [-5|20] "V" Vector__XXX
 SG_ PDM_wpVoltAvg : 16|16@1- (0.001,0) [-5|20] "V" Vector__XXX
 SG_ PDM_counterMsg408 : 0|4@1+ (1,0) [0|15] "" Vector__XXX

BO_ 409 PDM_409: 8 PDM
 SG_ PDM_teensyTemp : 48|16@1- (0.1,0) [-5|100] "degC" Vector__XXX
 SG_ PDM_wpDutyCycle : 32|8@1+ (1,0) [0|100] "Duty Cycle" Vector__XXX
 SG_ PDM_fanRightDutyCycle : 24|8@1+ (1,0) [0|100] "Duty Cycle" Vector__XXX
 SG_ PDM_fanLeftDutyCycle : 16|8@1+ (1,0) [0|100] "Duty Cycle" Vector__XXX
 SG_ PDM_counterMsg409 : 0|4@1+ (1,0) [0|15] "" Vector__XXX

BO_ 410 PDM_410: 8 PDM
 SG_ PDM_uptime : 0|32@1+ (1,0) [0|4294967295] "ms" Vector__XXX

BO_ 411 PDM_411: 8 PDM
 SG_ PDM_glvVoltMin : 48|16@1- (0.001,0) [-5|20] "V" Vector__XXX
 SG_ PDM_glvVoltMax : 32|16@1- (0.001,0) [-5|20] "V" Vector__XXX
 SG_ PDM_glvVoltAvg : 16|16@1- (0.001,0) [-5|20] "V" Vector__XXX
 SG_ PDM_counterMsg411 : 0|4@1+ (1,0) [0|15] "" Vector__XXX

BO_ 412 PDM_412: 8 PDM
 SG_ PDM_dataVoltMin : 48|16@1- (0.001,0) [-5|20] "V" Vector__XXX
 SG_ PDM_dataVoltMax : 32|16@1- (0.001,0) [-5|20] "V" Vector__XXX
 SG_ PDM_dataVoltAvg : 16|16@1- (0.001,0) [-5|20] "V" Vector__XXX
 SG_ PDM_counterMsg412 : 0|4@1+ (1,0) [0|15] "" Vector__XXX

BO_ 413 PDM_413: 8 PDM
 SG_ PDM_keepAliveVoltMin : 48|16@1- (0.001,0) [-5|20] "V" Vector__XXX
 SG_ PDM_keepAliveVoltMax : 32|16@1- (0.001,0) [-5|20] "V" Vector__XXX
 SG_ PDM_keepAliveVoltAvg : 16|16@1- (0.001,0) [-5|20] "V" Vector__XXX
 SG_ PDM_counterMsg413 : 0|4@1+ (1,0) [0|15] "" Vector__XXX

BO_ 414 PDM_414: 8 PDM
 SG_ PDM_runtimeMinutes : 48|16@1- (1,0) [-32768|32767] "mins" Vector__XXX
 SG_ PDM_runtimeHours : 32|16@1- (1,0) [-32768|32767] "hrs" Vector__XXX
 SG_ PDM_carMiles : 16|16@1- (0.1,0) [-3276.8|3276.7] "mi" Vector__XXX
 SG_ PDM_counterMsg414 : 0|4@1+ (1,0) [0|15] "" Vector__XXX

BO_ 450 MM52_450: 8 MM52
 SG_ MM52_ay : 32|16@1+ (0.0001274,-4.1745795) [0|0] "g" Vector__XXX
 SG_ MM52_yawRate : 0|16@1+ (0.005,-163.9) [0|0] "deg/sec" Vector__XXX

BO_ 451 MM52_451: 8 MM52
 SG_ MM52_az : 32|16@1+ (-0.0001274,4.1745795) [0|0] "g" Vector__XXX
 SG_ MM52_ax : 16|16@1+ (-0.0001274,4.1745795) [0|0] "g" Vector__XXX
 SG_ MM52_rollRate : 0|16@1+ (-0.005,163.9) [0|0] "deg/sec" Vector__XXX

BO_ 500 RAND_500: 8 RAND
 SG_ RAND_preRadPres : 16|16@1- (0.1,0) [-200|200] "kPa" Vector__XXX
 SG_ RAND_preRadTemp : 16|16@1- (0.1,0) [-20|130] "degC" Vector__XXX
 SG_ RAND_counterMsg500 : 0|4@1+ (1,0) [0|15] "" Vector__XXX

BO_ 501 RAND_501: 8 RAND
 SG_ RAND_postRadPres : 16|16@1- (0.1,0) [-200|200] "kPa" Vector__XXX
 SG_ RAND_postRadTemp : 16|16@1- (0.1,0) [-20|130] "degC" Vector__XXX
 SG_ RAND_counterMsg501 : 0|4@1+ (1,0) [0|15] "" Vector__XXX

CM_ SG_ 150 VCU_throttlePosition2 "TPS2";
CM_ SG_ 150 VCU_throttlePosition1 "TPS1";
CM_ SG_ 150 VCU_throttlePosition "Final throttle position";
CM_ SG_ 150 VCU_counterMsg150 "Counter Message 150";
CM_ SG_ 151 VCU_brakePressureR "Rear brake pressure";
CM_ SG_ 151 VCU_brakePressureF "Front brake pressure";
CM_ SG_ 151 VCU_brakeBias "Brake bias";
CM_ SG_ 151 VCU_counterMsg151 "Counter Message 151";
CM_ SG_ 152 VCU_rtmSound "Ready to move sound";
CM_ SG_ 152 VCU_mainMinusContactorState "Main minus contactor state (enumerated in DBC value table)";
CM_ SG_ 152 VCU_mainPlusContactorState "Main plus contactor state (enumerated in DBC value table)";
CM_ SG_ 152 VCU_prechargeContactorState "Precharge contactor state (enumerated in DBC value table)";
CM_ SG_ 152 VCU_dischargeContactorState "Discharge contactor state (enumerated in DBC value table)";
CM_ SG_ 152 VCU_vehicleState "Vehicle state (enumerated in DBC value table)";
CM_ SG_ 152 VCU_counterMsg152 "Counter Message 152";
CM_ SG_ 153 VCU_coolSwitch "Cool switch signal";
CM_ SG_ 153 VCU_pwrDownSwitch "Power down switch signal";
CM_ SG_ 153 VCU_pwrUpSwitch "Power up switch signal";
CM_ SG_ 153 VCU_startSwitch "Start switch signal";
CM_ SG_ 153 VCU_counterMsg153 "Counter Message 153";
CM_ SG_ 154 VCU_rotorTempFR "FR rotor temperature";
CM_ SG_ 154 VCU_rotorTempFL "FL rotor temperature";
CM_ SG_ 154 VCU_counterMsg154 "Counter Message 154";
CM_ SG_ 155 VCU_rotorTempRR "RR rotor temperature";
CM_ SG_ 155 VCU_rotorTempRL "RL rotor temperature";
CM_ SG_ 155 VCU_counterMsg155 "Counter Message 155";
CM_ SG_ 156 VCU_tireTempFLO "FLO tire temperature";
CM_ SG_ 156 VCU_tireTempFLM "FLM tire temperature";
CM_ SG_ 156 VCU_tireTempFLI "FLI tire temperature";
CM_ SG_ 156 VCU_counterMsg156 "Counter Message 156";
CM_ SG_ 157 VCU_tireTempFRO "FRO tire temperature";
CM_ SG_ 157 VCU_tireTempFRM "FRM tire temperature";
CM_ SG_ 157 VCU_tireTempFRI "FRI tire temperature";
CM_ SG_ 157 VCU_counterMsg157 "Counter Message 157";
CM_ SG_ 158 VCU_tireTempRLO "RLO tire temperature";
CM_ SG_ 158 VCU_tireTempRLM "RLM tire temperature";
CM_ SG_ 158 VCU_tireTempRLI "RLI tire temperature";
CM_ SG_ 158 VCU_counterMsg158 "Counter Message 158";
CM_ SG_ 159 VCU_tireTempRRO "RLO tire temperature";
CM_ SG_ 159 VCU_tireTempRRM "RLM tire temperature";
CM_ SG_ 159 VCU_tireTempRRI "RLI tire temperature";
CM_ SG_ 159 VCU_counterMsg159 "Counter Message 159";
CM_ SG_ 160 VCU_driveSpeed "Front wheel speed";
CM_ SG_ 160 VCU_counterMsg160 "Counter Message 160";
CM_ SG_ 161 VCU_flowRateMotorOut "Motor out flow rate";
CM_ SG_ 161 VCU_flowRateMotorIn "Motor in flow rate";
CM_ SG_ 161 VCU_flowRateInverterOut "Inverter out flow rate";
CM_ SG_ 161 VCU_counterMsg161 "Counter Message 161";
CM_ SG_ 162 VCU_az "Estimated vertical acceleration at CG";
CM_ SG_ 162 VCU_ay "Estimated lateral acceleration at CG";
CM_ SG_ 162 VCU_ax "Estimated longitudinal acceleration at CG";
CM_ SG_ 162 VCU_counterMsg162 "Counter Message 162";
CM_ SG_ 164 VCU_assistedTorque "Torque after brake regen";
CM_ SG_ 200 BMS_packSOC "This is the pack State of Charge";
CM_ SG_ 200 BMS_packVolt "This is the instantaneous total pack voltage value";
CM_ SG_ 200 BMS_packCurr "This is the current pack amperage value for the battery pack. This will report a constant 0 if no current sensor is selected";
CM_ SG_ 200 BMS_rollingCounter200 "Increments once every 100ms (max value is 255 and rolls over). Can be used to ensure data is updating";
CM_ SG_ 201 BMS_minPackVolt "This value is the mainimum pack voltage that the BMS is using to limit how low the pack voltage is allowed to be pulled down to";
CM_ SG_ 201 BMS_maxPackVolt "This value is the maximum pack voltage that the BMS is using to limit how high the pack voltage can be. This can be useful for communicating with chargers or charging stations expecting a maximum pack voltage value they are able to charge up to";
CM_ SG_ 201 BMS_packSummedVolt "This value is the sum of all the cells being monitored by the BMS and represents the overall pack voltage. It is essentially identical to the Pack Voltage value, except that it is reported wit ha higher resolution (0.01V versus 0.1V)";
CM_ SG_ 201 BMS_rollingCounter201 "Increments once every 100ms (max value is 255 and rolls over). Can be used to ensure data is updating";
CM_ SG_ 202 BMS_packResistance "This is the combined measured internal resistance for the entire battery pack";
CM_ SG_ 202 BMS_packAmphours "This is the calculated number of amphours remaining in the battery pack. This is used in part to calculate State of Charge";
CM_ SG_ 202 BMS_packSOH "This is the total state of health for the battery pack";
CM_ SG_ 202 BMS_packDOD "This value represents the total pack depth of discharge (that is, the total percent of the battery that has been discharged to this point). This value does not account for any Drift";
CM_ SG_ 202 BMS_rollingCounter202 "Increments once every 100ms (max value is 255 and rolls over). Can be used to ensure data is updating";
CM_ SG_ 203 BMS_internalTemp "This signed value is the internal temperature measured by the BMS (specifically, it is the temperature of the heatsink case)";
CM_ SG_ 203 BMS_avgTemp "This signed value is the average temperature measured in the battery back by the thermistors";
CM_ SG_ 203 BMS_lowestThermistorID "This is the ID of the lowest temperature thermistor being sensed by the BMS. The lowest possible value is 1";
CM_ SG_ 203 BMS_lowestTemp "This signed value is the lowest temperature measured in the battery pack";
CM_ SG_ 203 BMS_highestThermistorID "This is the ID of the highest temperature thermistor being sensed by the BMS. The lowest possible value is 1";
CM_ SG_ 203 BMS_highestTemp "This signed value is the highest temperature measured in the battery pack";
CM_ SG_ 203 BMS_rollingCounter203 "Increments once every 100ms (max value is 255 and rolls over). Can be used to ensure data is updating";
CM_ SG_ 204 BMS_avgCellVolt "This is the voltage of the average measured cell in the battery pack";
CM_ SG_ 204 BMS_highCellVolt "This is the voltage of the highest measured cell in the battery pack";
CM_ SG_ 204 BMS_lowCellVolt "This is the voltage of the lowest measured cell in the battery pack";
CM_ SG_ 204 BMS_rollingCounter204 "Increments once every 100ms (max value is 255 and rolls over). Can be used to ensure data is updating";
CM_ SG_ 205 BMS_avgCellOpenVolt "This is the Open Voltage of the average measured cell in the battery pack";
CM_ SG_ 205 BMS_highCellOpenVolt "This is the Open Voltage of the highest measured cell in the battery pack";
CM_ SG_ 205 BMS_lowCellOpenVolt "This is the Open Voltage of the lowest measured cell in the battery pack";
CM_ SG_ 205 BMS_rollingCounter205 "Increments once every 100ms (max value is 255 and rolls over). Can be used to ensure data is updating";
CM_ SG_ 206 BMS_avgCellInternalResistance "This is the Internal Resistance of the average measured cell in the battery pack";
CM_ SG_ 206 BMS_highCellInternalResistance "This is the Internal Resistance of the highest measured cell in the battery pack";
CM_ SG_ 206 BMS_lowCellInternalResistance "This is the Internal Resistance of the lowest measured cell in the battery pack";
CM_ SG_ 206 BMS_rollingCounter206 "Increments once every 100ms (max value is 255 and rolls over). Can be used to ensure data is updating";
CM_ SG_ 207 BMS_pwrInputVolt "This is the voltage of the power source that directly powers the BMS (12v-24v nominal for the standard Orion BMS, 12v-48v nominal for the Orion JR BMS). NOTE: This value will read lower than the actual input voltage seen at the BMS due to internal diode voltage drop. This is normal and this value should not be used as a precise measurement";
CM_ SG_ 207 BMS_minCellVolt "This value is the minimum cell voltage that the BMS is using to limit how low individual cell voltages are allowed to be pulled down to";
CM_ SG_ 207 BMS_maxCellVolt "This value is the maximum cell voltage that the BMS is using to limit how high individual cell voltages can be. This can be useful for communicating with chargers or charging stations expecting a maximum cell voltage that they are able to charge up to";
CM_ SG_ 207 BMS_rollingCounter207 "Increments once every 100ms (max value is 255 and rolls over). Can be used to ensure data is updating";
CM_ SG_ 208 BMS_highCellResistanceID "This value is the ID of the highest cell resistance measured by the BMS. The value is 1 based (valid range: 1-180)";
CM_ SG_ 208 BMS_lowCellResistanceID "This value is the ID of the lowest cell resistance measured by the BMS. The value is 1 based (valid range: 1-180)";
CM_ SG_ 208 BMS_highCellOpenVoltID "This value is the ID of the highest cell open (sitting) voltage measured by the BMS. The value is 1 based (valid range: 1-180)";
CM_ SG_ 208 BMS_lowCellOpenVoltID "This value is the ID of the lowest cell open (sitting) voltage measured by the BMS. The value is 1 based (valid range: 1-180)";
CM_ SG_ 208 BMS_highCellVoltID "This value is the ID of the highest cell voltage measured by the BMS. The value is 1 based (valid range: 1-180)";
CM_ SG_ 208 BMS_lowCellVoltID "This value is the ID of the lowest cell voltage measured by the BMS. The value is 1 based (valid range: 1-180)";
CM_ SG_ 208 BMS_rollingCounter208 "Increments once every 100ms (max value is 255 and rolls over). Can be used to ensure data is updating";
CM_ SG_ 209 BMS_totalPackADC "This is the raw voltage value from the total pack voltage sensor (NOT the sum of all the cell voltages). Only available on BMS models that support the separate total pack sensor";
CM_ SG_ 209 BMS_packChargeCurrLimkW "This is the pack Charge Current Limit expressed in kilowatts as opposed to amps";
CM_ SG_ 209 BMS_packChargeCurrLim "This is the pack Charge Current Limit. The value is, by default, reported as a positive value from 0 to whatever the maximum charge current limit is set to";
CM_ SG_ 209 BMS_rollingCounter209 "Increments once every 100ms (max value is 255 and rolls over). Can be used to ensure data is updating";
CM_ SG_ 210 BMS_packOpenVolt "This is the current total pack Open Voltage value";
CM_ SG_ 210 BMS_packDischargeCurrLimkW "This is the pack Discharge Current Limit expressed in kilowatts as opposed to amps";
CM_ SG_ 210 BMS_packDischargeCurrLim "This is the pack Discharge Current Limit. This value is, by default, reported as a positive value from 0 to whatever the maximum discharge current limit is set to";
CM_ SG_ 210 BMS_rollingCounter210 "Increments once every 100ms (max value is 255 and rolls over). Can be used to ensure data is updating";
CM_ SG_ 211 BMS_avgPackCurr "This is the AVERAGE current pack amperage value for the battery pack. This will report a constant 0 if no current sensor is selected. The average is taken over the last 1 second of operation so it will lag the instantaneous pack current value";
CM_ SG_ 211 BMS_maxPackCCL "This value is the programmed maximum continuous pack Charge Current Limit";
CM_ SG_ 211 BMS_maxPackDCL "This value is the programmed maximum continuous pack Discharge Current Limit";
CM_ SG_ 211 BMS_rollingCounter211 "Increments once every 100ms (max value is 255 and rolls over). Can be used to ensure data is updating";
CM_ SG_ 212 BMS_fanVolt "This is the raw voltage measured by the fan monitor circuit. This can be a maximum of 15V";
CM_ SG_ 212 BMS_adaptiveSOC "This is the calculated State of Charge value based on the Adaptive Total Capacity. As the BMS continues to learn more about the battery pack (specifically, how much capacity is actually in the pack versus how mush it is programmed to expect) this figure will become more accurate. It is expected for this value to differ, at least slightly, from the overall pack State of Charge parameter as that value is based on the programmed expected capacity, rather than the observed capacity";
CM_ SG_ 212 BMS_requestedFanSpeed "This is the current requested speed (0-6) of the battery fan";
CM_ SG_ 212 BMS_fanSpeed "This is the current speed (0-6) of the battery fan. The higher the speed, the faster the fan output should be";
CM_ SG_ 212 BMS_rollingCounter212 "Increments once every 100ms (max value is 255 and rolls over). Can be used to ensure data is updating";
CM_ SG_ 213 BMS_currLimStatus "This value is provided so the reasons for why a current limit either Charge Current Limit or Discharge Current Limit are being reduced by the BMS from the maximum allowable current. Look at utility manual";
CM_ SG_ 213 BMS_adaptiveAmphours "This is the Pack Amphours value equivalent based on the Adaptive Total Capacity metric. This is NOT the total capacity of the battery pack";
CM_ SG_ 213 BMS_adaptiveTotalCapacity "This is the total number of amphours that the BMS has 'observed' or learned during operation. Over time this will gradually be adjusted as the BMS continues to observe the battery pack";
CM_ SG_ 213 BMS_rollingCounter213 "Increments once every 100ms (max value is 255 and rolls over). Can be used to ensure data is updating";
CM_ SG_ 214 BMS_populatedCells "This represents the total number of populated (active) cells in the BMS. This can be equal or lower than the Max Cell Number";
CM_ SG_ 214 BMS_dtcStatus1 "This parameter contains the status of several BMS fault codes. Look at utility manual";
CM_ SG_ 214 BMS_totalPackCycles "This is the total number of cycles that the battery pack has been put through since the BMS has started keeping track. On revision-D BMS units and newer this value is stored over complete power loss, though on earlier hardware revisions this value is lost when all power is cut to the BMS. A battery cycle is defined as a net transfer of the total Amphour capacity of the pack. In other words, on a 40 Ahr battery one cycle would be a net transfer of 40 Amphours";
CM_ SG_ 214 BMS_maxCellNumber "The maximum number of cells that the BMS is capable of supporting";
CM_ SG_ 214 BMS_rollingCounter214 "Increments once every 100ms (max value is 255 and rolls over). Can be used to ensure data is updating";
CM_ SG_ 215 BMS_dtcStatus2 "This parameter contains the status of several BMS fault codes. Look at utility manual";
CM_ SG_ 215 BMS_failsafeStatus "Look at utility manual";
CM_ SG_ 215 BMS_relayState "Look at utility manual";
CM_ SG_ 215 BMS_rollingCounter215 "Increments once every 100ms (max value is 255 and rolls over). Can be used to ensure data is updating";
CM_ SG_ 216 BMS_j1772ACVolt "This is the AC voltage that the BMS is using for internal calculations. This can be provided to the BMS by the charger if it supports this functionality (must be CANBUS enabled and able to transmit the AC voltage). Otherwise the BMS may assume a certain voltage based on the observed AC current limit";
CM_ SG_ 216 BMS_j1772ACPwrLim "This is the calculated AC power limit (expressed in watts) that the charger is allowed to consume";
CM_ SG_ 216 BMS_j1772ACCurrLim "This is the raw AC current limit being published by the J1772 compatible charging station";
CM_ SG_ 216 BMS_j1772PlugState "This represents the current status (state) of the J1772 inlet on the vehicle. Look at utility manual";
CM_ SG_ 216 BMS_rollingCounter216 "Increments once every 100ms (max value is 255 and rolls over). Can be used to ensure data is updating";
CM_ SG_ 250 DD_teensyTemp "Teensy Board Temp";
CM_ SG_ 250 DD_boardTemp "Board Temp";
CM_ SG_ 250 DD_counterMsg250 "Counter Message 250";
CM_ SG_ 406451072 STMM_seg1ThermValAvg "amb";
CM_ SG_ 406451072 STMM_seg1ThermValHigh "amb";
CM_ SG_ 406451072 STMM_seg1ThermValLow "amb";
CM_ SG_ 406451073 STMM_seg2ThermValAvg "amb";
CM_ SG_ 406451073 STMM_seg2ThermValHigh "amb";
CM_ SG_ 406451073 STMM_seg2ThermValLow "amb";
CM_ SG_ 406451074 STMM_seg3ThermValAvg "amb";
CM_ SG_ 406451074 STMM_seg3ThermValHigh "amb";
CM_ SG_ 406451074 STMM_seg3ThermValLow "amb";
CM_ SG_ 406451075 STMM_seg4ThermValAvg "amb";
CM_ SG_ 406451075 STMM_seg4ThermValHigh "amb";
CM_ SG_ 406451075 STMM_seg4ThermValLow "amb";
CM_ SG_ 406451076 STMM_seg5ThermValAvg "amb";
CM_ SG_ 406451076 STMM_seg5ThermValHigh "amb";
CM_ SG_ 406451076 STMM_seg5ThermValLow "amb";
CM_ SG_ 406451077 STMM_seg6ThermValAvg "amb";
CM_ SG_ 406451077 STMM_seg6ThermValHigh "amb";
CM_ SG_ 406451077 STMM_seg6ThermValLow "amb";
CM_ SG_ 406451078 STMM_seg7ThermValAvg "amb";
CM_ SG_ 406451078 STMM_seg7ThermValHigh "amb";
CM_ SG_ 406451078 STMM_seg7ThermValLow "amb";
CM_ SG_ 406451079 STMM_seg8ThermValAvg "amb";
CM_ SG_ 406451079 STMM_seg8ThermValHigh "amb";
CM_ SG_ 406451079 STMM_seg8ThermValLow "amb";
CM_ SG_ 300 STMM_segmentTemp102 "amb";
CM_ SG_ 300 STMM_segmentTemp101 "amb";
CM_ SG_ 300 STMM_segmentTemp100 "amb";
CM_ SG_ 301 STMM_segmentTemp105 "amb";
CM_ SG_ 301 STMM_segmentTemp104 "amb";
CM_ SG_ 301 STMM_segmentTemp103 "amb";
CM_ SG_ 302 STMM_segmentTemp108 "amb";
CM_ SG_ 302 STMM_segmentTemp107 "amb";
CM_ SG_ 302 STMM_segmentTemp106 "amb";
CM_ SG_ 303 STMM_segmentTemp111 "amb";
CM_ SG_ 303 STMM_segmentTemp110 "amb";
CM_ SG_ 303 STMM_segmentTemp109 "amb";
CM_ SG_ 304 STMM_segmentTemp202 "amb";
CM_ SG_ 304 STMM_segmentTemp201 "amb";
CM_ SG_ 304 STMM_segmentTemp200 "amb";
CM_ SG_ 305 STMM_segmentTemp205 "amb";
CM_ SG_ 305 STMM_segmentTemp204 "amb";
CM_ SG_ 305 STMM_segmentTemp203 "amb";
CM_ SG_ 306 STMM_segmentTemp208 "amb";
CM_ SG_ 306 STMM_segmentTemp207 "amb";
CM_ SG_ 306 STMM_segmentTemp206 "amb";
CM_ SG_ 307 STMM_segmentTemp211 "amb";
CM_ SG_ 307 STMM_segmentTemp210 "amb";
CM_ SG_ 307 STMM_segmentTemp209 "amb";
CM_ SG_ 308 STMM_segmentTemp302 "amb";
CM_ SG_ 308 STMM_segmentTemp301 "amb";
CM_ SG_ 308 STMM_segmentTemp300 "amb";
CM_ SG_ 309 STMM_segmentTemp305 "amb";
CM_ SG_ 309 STMM_segmentTemp304 "amb";
CM_ SG_ 309 STMM_segmentTemp303 "amb";
CM_ SG_ 310 STMM_segmentTemp308 "amb";
CM_ SG_ 310 STMM_segmentTemp307 "amb";
CM_ SG_ 310 STMM_segmentTemp306 "amb";
CM_ SG_ 311 STMM_segmentTemp311 "amb";
CM_ SG_ 311 STMM_segmentTemp310 "amb";
CM_ SG_ 311 STMM_segmentTemp309 "amb";
CM_ SG_ 312 STMM_segmentTemp402 "amb";
CM_ SG_ 312 STMM_segmentTemp401 "amb";
CM_ SG_ 312 STMM_segmentTemp400 "amb";
CM_ SG_ 313 STMM_segmentTemp405 "amb";
CM_ SG_ 313 STMM_segmentTemp404 "amb";
CM_ SG_ 313 STMM_segmentTemp403 "amb";
CM_ SG_ 314 STMM_segmentTemp408 "amb";
CM_ SG_ 314 STMM_segmentTemp407 "amb";
CM_ SG_ 314 STMM_segmentTemp406 "amb";
CM_ SG_ 315 STMM_segmentTemp411 "amb";
CM_ SG_ 315 STMM_segmentTemp410 "amb";
CM_ SG_ 315 STMM_segmentTemp409 "amb";
CM_ SG_ 316 STMM_segmentTemp502 "amb";
CM_ SG_ 316 STMM_segmentTemp501 "amb";
CM_ SG_ 316 STMM_segmentTemp500 "amb";
CM_ SG_ 317 STMM_segmentTemp505 "amb";
CM_ SG_ 317 STMM_segmentTemp504 "amb";
CM_ SG_ 317 STMM_segmentTemp503 "amb";
CM_ SG_ 318 STMM_segmentTemp508 "amb";
CM_ SG_ 318 STMM_segmentTemp507 "amb";
CM_ SG_ 318 STMM_segmentTemp506 "amb";
CM_ SG_ 319 STMM_segmentTemp511 "amb";
CM_ SG_ 319 STMM_segmentTemp510 "amb";
CM_ SG_ 319 STMM_segmentTemp509 "amb";
CM_ SG_ 320 STMM_segmentTemp602 "amb";
CM_ SG_ 320 STMM_segmentTemp601 "amb";
CM_ SG_ 320 STMM_segmentTemp600 "amb";
CM_ SG_ 321 STMM_segmentTemp605 "amb";
CM_ SG_ 321 STMM_segmentTemp604 "amb";
CM_ SG_ 321 STMM_segmentTemp603 "amb";
CM_ SG_ 322 STMM_segmentTemp608 "amb";
CM_ SG_ 322 STMM_segmentTemp607 "amb";
CM_ SG_ 322 STMM_segmentTemp606 "amb";
CM_ SG_ 323 STMM_segmentTemp611 "amb";
CM_ SG_ 323 STMM_segmentTemp610 "amb";
CM_ SG_ 323 STMM_segmentTemp609 "amb";
CM_ SG_ 324 STMM_segmentTemp702 "amb";
CM_ SG_ 324 STMM_segmentTemp701 "amb";
CM_ SG_ 324 STMM_segmentTemp700 "amb";
CM_ SG_ 325 STMM_segmentTemp705 "amb";
CM_ SG_ 325 STMM_segmentTemp704 "amb";
CM_ SG_ 325 STMM_segmentTemp703 "amb";
CM_ SG_ 326 STMM_segmentTemp708 "amb";
CM_ SG_ 326 STMM_segmentTemp707 "amb";
CM_ SG_ 326 STMM_segmentTemp706 "amb";
CM_ SG_ 327 STMM_segmentTemp711 "amb";
CM_ SG_ 327 STMM_segmentTemp710 "amb";
CM_ SG_ 327 STMM_segmentTemp709 "amb";
CM_ SG_ 328 STMM_segmentTemp802 "amb";
CM_ SG_ 328 STMM_segmentTemp801 "amb";
CM_ SG_ 328 STMM_segmentTemp800 "amb";
CM_ SG_ 329 STMM_segmentTemp805 "amb";
CM_ SG_ 329 STMM_segmentTemp804 "amb";
CM_ SG_ 329 STMM_segmentTemp803 "amb";
CM_ SG_ 330 STMM_segmentTemp808 "amb";
CM_ SG_ 330 STMM_segmentTemp807 "amb";
CM_ SG_ 330 STMM_segmentTemp806 "amb";
CM_ SG_ 331 STMM_segmentTemp811 "amb";
CM_ SG_ 331 STMM_segmentTemp810 "amb";
CM_ SG_ 331 STMM_segmentTemp809 "amb";
CM_ SG_ 372 MM5_ay "Acceleration Y Axis";
CM_ SG_ 372 MM5_yawRate "Yaw Rate";
CM_ SG_ 376 MM5_ax "Acceleration X Axis";
CM_ SG_ 376 MM5_rollRate "Roll Rate";
CM_ SG_ 380 MM5_az "Acceleration Z Axis";
CM_ SG_ 400 PDM_coolingOverrideActive "Cooling Override State";
CM_ SG_ 400 PDM_vehicleState "0 = off, 1 = on, 2 = cooldown";
CM_ SG_ 400 PDM_brakelightVoltAvg "Brakelight Average Voltage";
CM_ SG_ 400 PDM_boardTemp "Board Temperature";
CM_ SG_ 400 PDM_counterMsg400 "Counter Message 400";
CM_ SG_ 401 PDM_pdmCurrentMin "PDM Minimum Current";
CM_ SG_ 401 PDM_pdmCurrentMax "PDM Maximum Current";
CM_ SG_ 401 PDM_pdmCurrentAvg "PDM Average Current";
CM_ SG_ 401 PDM_counterMsg401 "Counter Message 401";
CM_ SG_ 402 PDM_pdmVoltMin "PDM Minimum Voltage";
CM_ SG_ 402 PDM_pdmVoltMax "PDM Maximum Voltage";
CM_ SG_ 402 PDM_pdmVoltAvg "PDM Average Voltage";
CM_ SG_ 402 PDM_counterMsg402 "Counter Message 402";
CM_ SG_ 403 PDM_fanRightCurrentMin "Right Fan Minimum Current";
CM_ SG_ 403 PDM_fanRightCurrentMax "Right Fan Maximum Current";
CM_ SG_ 403 PDM_fanRightCurrentAvg "Right Fan Average Current";
CM_ SG_ 403 PDM_counterMsg403 "Counter Message 403";
CM_ SG_ 404 PDM_fanRightVoltMin "Right Fan Minimum Voltage";
CM_ SG_ 404 PDM_fanRightVoltMax "Right Fan Maximum Voltage";
CM_ SG_ 404 PDM_fanRightVoltAvg "Right Fan Average Voltage";
CM_ SG_ 404 PDM_counterMsg404 "Counter Message 404";
CM_ SG_ 405 PDM_fanLeftCurrentMin "Left Fan Minimum Current";
CM_ SG_ 405 PDM_fanLeftCurrentMax "Left Fan Maximum Current";
CM_ SG_ 405 PDM_fanLeftCurrentAvg "Left Fan Average Current";
CM_ SG_ 405 PDM_counterMsg405 "Counter Message 405";
CM_ SG_ 406 PDM_fanLeftVoltMin "Left Fan Minimum Voltage";
CM_ SG_ 406 PDM_fanLeftVoltMax "Left Fan Maximum Voltage";
CM_ SG_ 406 PDM_fanLeftVoltAvg "Left Fan Average Voltage";
CM_ SG_ 406 PDM_counterMsg406 "Counter Message 406";
CM_ SG_ 407 PDM_wpCurrentMin "Water Pump Minimum Current";
CM_ SG_ 407 PDM_wpCurrentMax "Water Pump Maximum Current";
CM_ SG_ 407 PDM_wpCurrentAvg "Water Pump Average Current";
CM_ SG_ 407 PDM_counterMsg407 "Counter Message 407";
CM_ SG_ 408 PDM_wpVoltMin "Water Pump Minimum Voltage";
CM_ SG_ 408 PDM_wpVoltMax "Water Pump Maximum Voltage";
CM_ SG_ 408 PDM_wpVoltAvg "Water Pump Average Voltage";
CM_ SG_ 408 PDM_counterMsg408 "Counter Message 408";
CM_ SG_ 409 PDM_teensyTemp "Teensy Board Temperature";
CM_ SG_ 409 PDM_wpDutyCycle "Water Pump Duty Cycle";
CM_ SG_ 409 PDM_fanRightDutyCycle "Right Fan Duty Cycle";
CM_ SG_ 409 PDM_fanLeftDutyCycle "Left Fan Duty Cycle";
CM_ SG_ 409 PDM_counterMsg409 "Counter Message 409";
CM_ SG_ 410 PDM_uptime "PDM Teensy Uptime";
CM_ SG_ 411 PDM_glvVoltMin "GLV Minimum Voltage";
CM_ SG_ 411 PDM_glvVoltMax "GLV Maximum Voltage";
CM_ SG_ 411 PDM_glvVoltAvg "GLV Average Voltage";
CM_ SG_ 411 PDM_counterMsg411 "Counter Message 411";
CM_ SG_ 412 PDM_dataVoltMin "Data Minimum Voltage";
CM_ SG_ 412 PDM_dataVoltMax "Data Maximum Voltage";
CM_ SG_ 412 PDM_dataVoltAvg "Data Average Voltage";
CM_ SG_ 412 PDM_counterMsg412 "Counter Message 412";
CM_ SG_ 413 PDM_keepAliveVoltMin "Keep Alive Minimum Voltage";
CM_ SG_ 413 PDM_keepAliveVoltMax "Keep Alive Maximum Voltage";
CM_ SG_ 413 PDM_keepAliveVoltAvg "Keep Alive Average Voltage";
CM_ SG_ 413 PDM_counterMsg413 "Counter Message 413";
CM_ SG_ 414 PDM_runtimeMinutes "Runtime Minutes";
CM_ SG_ 414 PDM_runtimeHours "Runtime Hours";
CM_ SG_ 414 PDM_carMiles "Car Miles";
CM_ SG_ 414 PDM_counterMsg414 "Counter Message 414";
CM_ SG_ 450 MM52_ay "Acceleration Y Axis";
CM_ SG_ 450 MM52_yawRate "Yaw Rate";
CM_ SG_ 451 MM52_az "Acceleration Z Axis";
CM_ SG_ 451 MM52_ax "Acceleration X Axis";
CM_ SG_ 451 MM52_rollRate "Roll Rate";
CM_ SG_ 500 RAND_preRadPres "Pre-radiator pressure";
CM_ SG_ 500 RAND_preRadTemp "Pre-radiator temperature";
CM_ SG_ 500 RAND_counterMsg500 "Counter Message 500";
CM_ SG_ 501 RAND_postRadPres "Post-radiator pressure";
CM_ SG_ 501 RAND_postRadTemp "Post-radiator temperature";
CM_ SG_ 501 RAND_counterMsg501 "Counter Message 501";
BA_DEF_  "BusType" STRING ;
BA_DEF_DEF_  "BusType" "CAN";
VAL_ 152 VCU_mainMinusContactorState 2 "Open" 1 "Close" 0 "Faulted" ;
VAL_ 152 VCU_mainPlusContactorState 2 "Open" 1 "Close" 0 "Faulted" ;
VAL_ 152 VCU_prechargeContactorState 2 "Open" 1 "Close" 0 "Faulted" ;
VAL_ 152 VCU_dischargeContactorState 2 "Open" 1 "Close" 0 "Faulted" ;
VAL_ 152 VCU_vehicleState 8 "Faulted" 7 "ReadyToMove" 6 "Standby" 5 "PrechargeComplete" 4 "PrechargeTimeout" 3 "Precharge" 2 "PrechargeReady" 1 "StartDelay" 0 "Off" ;
